VERSION "dbc-export 1 2026.26.6.5"

NS_ :

BS_:

BU_: APP APS BMS CC CMP CMPD CP DAS DI DIF DIR EPBL EPBR EVSE FC GTW HCML HCMR HVP ICR PCS PCS2 PLG PM PMF PMR PTC SCCM SCM SCS SDCR TAS UMC V2G VC VCBATT VCBATT0 VCBATT1 VCBATT2 VCFRONT VCFRONT1 VCFRONT2 VCLEFT VCRIGHT VCSEAT2L VCSEAT2R VCSEC

BO_ 968 EPBL_alertMatrix: 8 EPBL
 SG_ EPBL_matrixIndex M : 0|4@1+ (1,0) [0|15] "" Vector__XXX
 SG_ EPBL_a001_WatchdogReset m0 : 4|1@1+ (1,0) [0|1] "" Vector__XXX
 SG_ EPBL_a002_PowerLossReset m0 : 5|1@1+ (1,0) [0|1] "" Vector__XXX
 SG_ EPBL_a003_SWAssertion m0 : 6|1@1+ (1,0) [0|1] "" Vector__XXX
 SG_ EPBL_a005_CANTXError m0 : 8|1@1+ (1,0) [0|1] "" Vector__XXX
 SG_ EPBL_a006_CANTX_cyclicError m0 : 9|1@1+ (1,0) [0|1] "" Vector__XXX
 SG_ EPBL_a012_CPUReset m0 : 15|1@1+ (1,0) [0|1] "" Vector__XXX
 SG_ EPBL_a013_AlertManagerFault m0 : 16|1@1+ (1,0) [0|1] "" Vector__XXX
 SG_ EPBL_a015_NVMMError m0 : 18|1@1+ (1,0) [0|1] "" Vector__XXX
 SG_ EPBL_a016_NVMMRecordError m0 : 19|1@1+ (1,0) [0|1] "" Vector__XXX
 SG_ EPBL_a021_TaskSchedulerError m0 : 24|1@1+ (1,0) [0|1] "" Vector__XXX
 SG_ EPBL_a022_TaskInitError m0 : 25|1@1+ (1,0) [0|1] "" Vector__XXX
 SG_ EPBL_a029_CoreDump m0 : 32|1@1+ (1,0) [0|1] "" Vector__XXX
 SG_ EPBL_a030_ECULogUploadRequest m0 : 33|1@1+ (1,0) [0|1] "" Vector__XXX
 SG_ EPBL_a031_UDSActive m0 : 34|1@1+ (1,0) [0|1] "" Vector__XXX
 SG_ EPBL_a041_HighCPULoad m0 : 44|1@1+ (1,0) [0|1] "" Vector__XXX
 SG_ EPBL_a042_HighStackUsage m0 : 45|1@1+ (1,0) [0|1] "" Vector__XXX
 SG_ EPBL_a043_Task1msError m0 : 46|1@1+ (1,0) [0|1] "" Vector__XXX
 SG_ EPBL_a044_Task10msError m0 : 47|1@1+ (1,0) [0|1] "" Vector__XXX
 SG_ EPBL_a045_Task100msError m0 : 48|1@1+ (1,0) [0|1] "" Vector__XXX
 SG_ EPBL_a046_Task1000msError m0 : 49|1@1+ (1,0) [0|1] "" Vector__XXX
 SG_ EPBL_a057_HVP_MIA m0 : 60|1@1+ (1,0) [0|1] "" Vector__XXX
 SG_ EPBL_a058_inputRHighSyncDebug m0 : 61|1@1+ (1,0) [0|1] "" Vector__XXX
 SG_ EPBL_a059_inputResistanceHigh m0 : 62|1@1+ (1,0) [0|1] "" Vector__XXX
 SG_ EPBL_a060_engineeringBuild m0 : 63|1@1+ (1,0) [0|1] "" Vector__XXX
 SG_ EPBL_a061_XCPConnected m1 : 4|1@1+ (1,0) [0|1] "" Vector__XXX
 SG_ EPBL_a062_XCPWasConnected m1 : 5|1@1+ (1,0) [0|1] "" Vector__XXX
 SG_ EPBL_a063_SwitchFault m1 : 6|1@1+ (1,0) [0|1] "" Vector__XXX
 SG_ EPBL_a064_busSleepReqTimeout m1 : 7|1@1+ (1,0) [0|1] "" Vector__XXX
 SG_ EPBL_a081_APP_MIA m1 : 24|1@1+ (1,0) [0|1] "" Vector__XXX
 SG_ EPBL_a082_VCRIGHT_IPC_MIA m1 : 25|1@1+ (1,0) [0|1] "" Vector__XXX
 SG_ EPBL_a083_VCLEFT_IPC_MIA m1 : 26|1@1+ (1,0) [0|1] "" Vector__XXX
 SG_ EPBL_a084_TPMS_MIA m1 : 27|1@1+ (1,0) [0|1] "" Vector__XXX
 SG_ EPBL_a085_CCCM_MIA m1 : 28|1@1+ (1,0) [0|1] "" Vector__XXX
 SG_ EPBL_a086_VCBATT_MIA m1 : 29|1@1+ (1,0) [0|1] "" Vector__XXX
 SG_ EPBL_a087_DIREL_MIA m1 : 30|1@1+ (1,0) [0|1] "" Vector__XXX
 SG_ EPBL_a088_DIRER_MIA m1 : 31|1@1+ (1,0) [0|1] "" Vector__XXX
 SG_ EPBL_a089_IBST_MIA m1 : 32|1@1+ (1,0) [0|1] "" Vector__XXX
 SG_ EPBL_a090_APS_MIA m1 : 33|1@1+ (1,0) [0|1] "" Vector__XXX
 SG_ EPBL_a091_CMPD_MIA m1 : 34|1@1+ (1,0) [0|1] "" Vector__XXX
 SG_ EPBL_a092_VCSEATD_MIA m1 : 35|1@1+ (1,0) [0|1] "" Vector__XXX
 SG_ EPBL_a093_VCSEATP_MIA m1 : 36|1@1+ (1,0) [0|1] "" Vector__XXX
 SG_ EPBL_a094_EPAS3P_MIA m1 : 37|1@1+ (1,0) [0|1] "" Vector__XXX
 SG_ EPBL_a095_CHG_MIA m1 : 38|1@1+ (1,0) [0|1] "" Vector__XXX
 SG_ EPBL_a096_OCS1P_MIA m1 : 39|1@1+ (1,0) [0|1] "" Vector__XXX
 SG_ EPBL_a097_CMP_MIA m1 : 40|1@1+ (1,0) [0|1] "" Vector__XXX
 SG_ EPBL_a098_DIR_MIA m1 : 41|1@1+ (1,0) [0|1] "" Vector__XXX
 SG_ EPBL_a099_PARK_MIA m1 : 42|1@1+ (1,0) [0|1] "" Vector__XXX
 SG_ EPBL_a100_CANbus_MIA m1 : 43|1@1+ (1,0) [0|1] "" Vector__XXX
 SG_ EPBL_a101_PM_MIA m1 : 44|1@1+ (1,0) [0|1] "" Vector__XXX
 SG_ EPBL_a102_PTC_MIA m1 : 45|1@1+ (1,0) [0|1] "" Vector__XXX
 SG_ EPBL_a103_CP_MIA m1 : 46|1@1+ (1,0) [0|1] "" Vector__XXX
 SG_ EPBL_a104_DAS_MIA m1 : 47|1@1+ (1,0) [0|1] "" Vector__XXX
 SG_ EPBL_a105_TAS_MIA m1 : 48|1@1+ (1,0) [0|1] "" Vector__XXX
 SG_ EPBL_a106_PCS_MIA m1 : 49|1@1+ (1,0) [0|1] "" Vector__XXX
 SG_ EPBL_a107_BMS_MIA m1 : 50|1@1+ (1,0) [0|1] "" Vector__XXX
 SG_ EPBL_a108_DIF_MIA m1 : 51|1@1+ (1,0) [0|1] "" Vector__XXX
 SG_ EPBL_a109_RCM_MIA m1 : 52|1@1+ (1,0) [0|1] "" Vector__XXX
 SG_ EPBL_a110_GTW_MIA m1 : 53|1@1+ (1,0) [0|1] "" Vector__XXX
 SG_ EPBL_a111_EPBR_MIA m1 : 54|1@1+ (1,0) [0|1] "" Vector__XXX
 SG_ EPBL_a112_EPBL_MIA m1 : 55|1@1+ (1,0) [0|1] "" Vector__XXX
 SG_ EPBL_a113_UI_MIA m1 : 56|1@1+ (1,0) [0|1] "" Vector__XXX
 SG_ EPBL_a114_ESP_MIA m1 : 57|1@1+ (1,0) [0|1] "" Vector__XXX
 SG_ EPBL_a115_VCSEC_MIA m1 : 58|1@1+ (1,0) [0|1] "" Vector__XXX
 SG_ EPBL_a116_VCRIGHT_MIA m1 : 59|1@1+ (1,0) [0|1] "" Vector__XXX
 SG_ EPBL_a117_VCLEFT_MIA m1 : 60|1@1+ (1,0) [0|1] "" Vector__XXX
 SG_ EPBL_a118_VCFRONT_MIA m1 : 61|1@1+ (1,0) [0|1] "" Vector__XXX
 SG_ EPBL_a119_SCCM_MIA m1 : 62|1@1+ (1,0) [0|1] "" Vector__XXX
 SG_ EPBL_a120_DI_DRIVE_MIA m1 : 63|1@1+ (1,0) [0|1] "" Vector__XXX
 SG_ EPBL_a121_nDriveFault m2 : 4|1@1+ (1,0) [0|1] "" Vector__XXX
 SG_ EPBL_a122_Oc m2 : 5|1@1+ (1,0) [0|1] "" Vector__XXX
 SG_ EPBL_a123_Uc m2 : 6|1@1+ (1,0) [0|1] "" Vector__XXX
 SG_ EPBL_a124_calOutOfBounds m2 : 7|1@1+ (1,0) [0|1] "" Vector__XXX
 SG_ EPBL_a125_IdleVMismatch m2 : 8|1@1+ (1,0) [0|1] "" Vector__XXX
 SG_ EPBL_a126_MotorNVoltLow m2 : 9|1@1+ (1,0) [0|1] "" Vector__XXX
 SG_ EPBL_a127_MotorNVoltHigh m2 : 10|1@1+ (1,0) [0|1] "" Vector__XXX
 SG_ EPBL_a128_MotorPVoltHigh m2 : 11|1@1+ (1,0) [0|1] "" Vector__XXX
 SG_ EPBL_a129_ICR_MIA m2 : 12|1@1+ (1,0) [0|1] "" Vector__XXX
 SG_ EPBL_a130_BB_MIA m2 : 13|1@1+ (1,0) [0|1] "" Vector__XXX
 SG_ EPBL_a131_RCU_MIA m2 : 14|1@1+ (1,0) [0|1] "" Vector__XXX
 SG_ EPBL_a132_VCBATT1_MIA m2 : 15|1@1+ (1,0) [0|1] "" Vector__XXX
 SG_ EPBL_a133_VCBATT2_MIA m2 : 16|1@1+ (1,0) [0|1] "" Vector__XXX
 SG_ EPBL_a134_NvOv m2 : 17|1@1+ (1,0) [0|1] "" Vector__XXX
 SG_ EPBL_a135_NvUv m2 : 18|1@1+ (1,0) [0|1] "" Vector__XXX
 SG_ EPBL_a136_PvOv m2 : 19|1@1+ (1,0) [0|1] "" Vector__XXX
 SG_ EPBL_a137_PvUv m2 : 20|1@1+ (1,0) [0|1] "" Vector__XXX
 SG_ EPBL_a138_NvmDualFailure m2 : 21|1@1+ (1,0) [0|1] "" Vector__XXX
 SG_ EPBL_a139_NvmRedundancyLoss m2 : 22|1@1+ (1,0) [0|1] "" Vector__XXX
 SG_ EPBL_a140_NvmSlowWrite m2 : 23|1@1+ (1,0) [0|1] "" Vector__XXX
 SG_ EPBL_a141_invalidState m2 : 24|1@1+ (1,0) [0|1] "" Vector__XXX
 SG_ EPBL_a170_12vOv m2 : 53|1@1+ (1,0) [0|1] "" Vector__XXX
 SG_ EPBL_a171_12vUv m2 : 54|1@1+ (1,0) [0|1] "" Vector__XXX
 SG_ EPBL_a172_SPI_MIA m2 : 55|1@1+ (1,0) [0|1] "" Vector__XXX
 SG_ EPBL_a173_hiCurrentMissing m2 : 56|1@1+ (1,0) [0|1] "" Vector__XXX
 SG_ EPBL_a174_csmReleaseFailed m2 : 57|1@1+ (1,0) [0|1] "" Vector__XXX
 SG_ EPBL_a175_csmReleaseRetry m2 : 58|1@1+ (1,0) [0|1] "" Vector__XXX
 SG_ EPBL_a176_csmApplyFailed m2 : 59|1@1+ (1,0) [0|1] "" Vector__XXX
 SG_ EPBL_a177_csmApplyRetry m2 : 60|1@1+ (1,0) [0|1] "" Vector__XXX
 SG_ EPBL_a178_caliperStateUnknown m2 : 61|1@1+ (1,0) [0|1] "" Vector__XXX
 SG_ EPBL_a179_epbProblem m2 : 62|1@1+ (1,0) [0|1] "" Vector__XXX
 SG_ EPBL_a180_dynamicActive m2 : 63|1@1+ (1,0) [0|1] "" Vector__XXX
 SG_ EPBL_a181_TooSteepGradeToPark m3 : 4|1@1+ (1,0) [0|1] "" Vector__XXX
 SG_ EPBL_a182_OneEPBAppliedUnsecEnv m3 : 5|1@1+ (1,0) [0|1] "" Vector__XXX
 SG_ EPBL_a183_cdpNotAvailable m3 : 6|1@1+ (1,0) [0|1] "" Vector__XXX
 SG_ EPBL_a184_dynamicParkAbort m3 : 7|1@1+ (1,0) [0|1] "" Vector__XXX
 SG_ EPBL_a185_summonAborted m3 : 8|1@1+ (1,0) [0|1] "" Vector__XXX
 SG_ EPBL_a186_externalParkAbort m3 : 9|1@1+ (1,0) [0|1] "" Vector__XXX
 SG_ EPBL_a187_cdpDynamic m3 : 10|1@1+ (1,0) [0|1] "" Vector__XXX
 SG_ EPBL_a188_epbDynamic m3 : 11|1@1+ (1,0) [0|1] "" Vector__XXX
 SG_ EPBL_a189_epbDynamicParkCanceled m3 : 12|1@1+ (1,0) [0|1] "" Vector__XXX
 SG_ EPBL_a190_csmApplyDegraded m3 : 13|1@1+ (1,0) [0|1] "" Vector__XXX
 SG_ EPBL_a191_csmReleaseDegraded m3 : 14|1@1+ (1,0) [0|1] "" Vector__XXX
 SG_ EPBL_a195_parkForDriverIsLeaving m3 : 18|1@1+ (1,0) [0|1] "" Vector__XXX
 SG_ EPBL_a196_freeRollModeActive m3 : 19|1@1+ (1,0) [0|1] "" Vector__XXX
 SG_ EPBL_a197_freeRollModeAtSpeed m3 : 20|1@1+ (1,0) [0|1] "" Vector__XXX
 SG_ EPBL_a198_holdClampComplete m3 : 21|1@1+ (1,0) [0|1] "" Vector__XXX
 SG_ EPBL_a200_PmUnparkNotAllowed m3 : 23|1@1+ (1,0) [0|1] "" Vector__XXX
 SG_ EPBL_a202_remoteEpbConfigIncompa m3 : 25|1@1+ (1,0) [0|1] "" Vector__XXX
 SG_ EPBL_a203_hwBrakeTypeMismatch m3 : 26|1@1+ (1,0) [0|1] "" Vector__XXX
 SG_ EPBL_a210_parkForDriverIsLeaving m3 : 33|1@1+ (1,0) [0|1] "" Vector__XXX
 SG_ EPBL_a216_SPI_MIA_debugData1 m3 : 39|1@1+ (1,0) [0|1] "" Vector__XXX
 SG_ EPBL_a217_SPI_MIA_debugData2 m3 : 40|1@1+ (1,0) [0|1] "" Vector__XXX
 SG_ EPBL_a225_epbActiveDecel m3 : 48|1@1+ (1,0) [0|1] "" Vector__XXX
 SG_ EPBL_a241_diOutputLocked m4 : 4|1@1+ (1,0) [0|1] "" Vector__XXX
 SG_ EPBL_a242_hvOutputLocked m4 : 5|1@1+ (1,0) [0|1] "" Vector__XXX
 SG_ EPBL_a243_bdwUnavailable m4 : 6|1@1+ (1,0) [0|1] "" Vector__XXX
 SG_ EPBL_a244_WinchModeActive m4 : 7|1@1+ (1,0) [0|1] "" Vector__XXX
 SG_ EPBL_a245_serviceModeActive m4 : 8|1@1+ (1,0) [0|1] "" Vector__XXX
 SG_ EPBL_a246_idleFaultApply m4 : 9|1@1+ (1,0) [0|1] "" Vector__XXX
 SG_ EPBL_a247_csmDynamicApplyRetry m4 : 10|1@1+ (1,0) [0|1] "" Vector__XXX
 SG_ EPBL_a248_csmDynamicApplyFailed m4 : 11|1@1+ (1,0) [0|1] "" Vector__XXX
 SG_ EPBL_a249_idleFaultRelease m4 : 12|1@1+ (1,0) [0|1] "" Vector__XXX
 SG_ EPBL_a250_WinchModeCanceled m4 : 13|1@1+ (1,0) [0|1] "" Vector__XXX
 SG_ EPBL_a251_currentVarianceHigh m4 : 14|1@1+ (1,0) [0|1] "" Vector__XXX
 SG_ EPBL_a252_winchModePending m4 : 15|1@1+ (1,0) [0|1] "" Vector__XXX
 SG_ EPBL_a253_esmReleaseBlocked m4 : 16|1@1+ (1,0) [0|1] "" Vector__XXX
 SG_ EPBL_a254_showStalkParkButtonFau m4 : 17|1@1+ (1,0) [0|1] "" Vector__XXX
 SG_ EPBL_a256_epbSystemApply m4 : 19|1@1+ (1,0) [0|1] "" Vector__XXX
 SG_ EPBL_a261_winchModeWithoutSteeri m4 : 24|1@1+ (1,0) [0|1] "" Vector__XXX
 SG_ EPBL_a262_cannotPrepareWinchMode m4 : 25|1@1+ (1,0) [0|1] "" Vector__XXX
 SG_ EPBL_a263_epbRecoveryPark m4 : 26|1@1+ (1,0) [0|1] "" Vector__XXX
 SG_ EPBL_a264_winchModeDeactivated m4 : 27|1@1+ (1,0) [0|1] "" Vector__XXX
 SG_ EPBL_a272_vhclPwrStateMsmtch m4 : 35|1@1+ (1,0) [0|1] "" Vector__XXX
 SG_ EPBL_a300_leftRightConfusion m4 : 63|1@1+ (1,0) [0|1] "" Vector__XXX
 SG_ EPBL_a301_oocSpeedViolation m5 : 4|1@1+ (1,0) [0|1] "" Vector__XXX
 SG_ EPBL_a302_csmLongRelease m5 : 5|1@1+ (1,0) [0|1] "" Vector__XXX
 SG_ EPBL_a303_clampingOccuredEarly m5 : 6|1@1+ (1,0) [0|1] "" Vector__XXX
 SG_ EPBL_a304_rearSeatControllerEFus m5 : 7|1@1+ (1,0) [0|1] "" Vector__XXX
 SG_ EPBL_a305_premiumAmpEFuseTrip m5 : 8|1@1+ (1,0) [0|1] "" Vector__XXX
 SG_ EPBL_a330_parkForApIsLeaving m5 : 33|1@1+ (1,0) [0|1] "" Vector__XXX
 SG_ EPBL_a350_ensOutOfRange m5 : 53|1@1+ (1,0) [0|1] "" Vector__XXX
 SG_ EPBL_a352_audioCurrentSpikeData m5 : 55|1@1+ (1,0) [0|1] "" Vector__XXX
 SG_ EPBL_a353_missingSpeedUnableToPa m5 : 56|1@1+ (1,0) [0|1] "" Vector__XXX
 SG_ EPBL_a354_parkedForLowBrakeFluid m5 : 57|1@1+ (1,0) [0|1] "" Vector__XXX
 SG_ EPBL_a355_brakeHwAndEpbHwMismatc m5 : 58|1@1+ (1,0) [0|1] "" Vector__XXX
 SG_ EPBL_a356_parkingForStationaryDe m5 : 59|1@1+ (1,0) [0|1] "" Vector__XXX
 SG_ EPBL_a357_brakesTooHotForSlope m5 : 60|1@1+ (1,0) [0|1] "" Vector__XXX
 SG_ EPBL_a358_brakesTooHotForSlopeWi m5 : 61|1@1+ (1,0) [0|1] "" Vector__XXX
 SG_ EPBL_a360_ibstBrakeSwitchInvalid m5 : 63|1@1+ (1,0) [0|1] "" Vector__XXX
 SG_ EPBL_a361_espBrakeSwitchInvalid m6 : 4|1@1+ (1,0) [0|1] "" Vector__XXX
 SG_ EPBL_a362_ibstPressedEspNotPress m6 : 5|1@1+ (1,0) [0|1] "" Vector__XXX
 SG_ EPBL_a363_ibstNotPressedEspPress m6 : 6|1@1+ (1,0) [0|1] "" Vector__XXX
 SG_ EPBL_a364_espMasterCylCompOverTh m6 : 7|1@1+ (1,0) [0|1] "" Vector__XXX
 SG_ EPBL_a365_TooSteepToParkWithTrai m6 : 8|1@1+ (1,0) [0|1] "" Vector__XXX
 SG_ EPBL_a366_TooSteepToParkWithTrai m6 : 9|1@1+ (1,0) [0|1] "" Vector__XXX
 SG_ EPBL_a370_imposterDetected m6 : 13|1@1+ (1,0) [0|1] "" Vector__XXX
 SG_ EPBL_a380_canError m6 : 23|1@1+ (1,0) [0|1] "" Vector__XXX
 SG_ EPBL_a381_LIPC_canFault m6 : 24|1@1+ (1,0) [0|1] "" Vector__XXX
 SG_ EPBL_a382_CH_canFault m6 : 25|1@1+ (1,0) [0|1] "" Vector__XXX

BO_ 1992 EPBL_info: 8 EPBL
 SG_ EPBL_infoIndex M : 0|8@1+ (1,0) [0|255] "" Vector__XXX
 SG_ EPBL_infoBuildType m10 : 8|3@1+ (1,0) [0|7] "" Vector__XXX
 SG_ EPBL_infoBuildConfigId m10 : 16|16@1+ (1,0) [0|65535] "" Vector__XXX
 SG_ EPBL_infoHardwareId m10 : 32|16@1+ (1,0) [0|65535] "" Vector__XXX
 SG_ EPBL_infoComponentId m10 : 48|16@1+ (1,0) [0|65535] "" Vector__XXX
 SG_ EPBL_infoPcbaId m11 : 8|8@1+ (1,0) [0|255] "" Vector__XXX
 SG_ EPBL_infoAssemblyId m11 : 16|8@1+ (1,0) [0|254] "" Vector__XXX
 SG_ EPBL_infoUsageId m11 : 24|16@1+ (1,0) [0|65535] "" Vector__XXX
 SG_ EPBL_infoSubUsageId m11 : 40|16@1+ (1,0) [0|65535] "" Vector__XXX
 SG_ EPBL_infoAppCrc m13 : 8|32@1+ (1,0) [0|4294967295] "" Vector__XXX
 SG_ EPBL_infoAppGitHash m17 : 8|56@1+ (1,0) [0|7.20575940379e+16] "" Vector__XXX
 SG_ EPBL_infoBootGitHash m18 : 8|56@1+ (1,0) [0|7.20575940379e+16] "" Vector__XXX
 SG_ EPBL_infoPlatformType m19 : 8|8@1+ (1,0) [0|255] "" Vector__XXX
 SG_ EPBL_infoBootUdsProtoVersion m20 : 8|16@1+ (1,0) [0|65535] "" Vector__XXX
 SG_ EPBL_infoBootCrc m20 : 24|32@1+ (1,0) [0|4294967295] "" Vector__XXX

BO_ 648 EPBL_internalStatus: 8 EPBL
 SG_ EPBL_unitStatus : 0|5@1+ (1,0) [0|31] "" Vector__XXX
 SG_ EPBL_unitFaultStatus : 5|2@1+ (1,0) [0|3] "" Vector__XXX
 SG_ EPBL_summonState : 8|3@1+ (1,0) [0|7] "" Vector__XXX
 SG_ EPBL_disconnected : 11|1@1+ (1,0) [0|1] "" Vector__XXX
 SG_ EPBL_pistonTouchingRotor : 12|1@1+ (1,0) [0|1] "" Vector__XXX
 SG_ EPBL_csmFaultReason : 13|5@1+ (1,0) [0|31] "" Vector__XXX
 SG_ EPBL_esmOperationTrigger : 18|6@1+ (1,0) [0|63] "" Vector__XXX
 SG_ EPBL_summonFaultReason : 24|5@1+ (1,0) [0|31] "" Vector__XXX
 SG_ EPBL_localServiceModeActive : 29|1@1+ (1,0) [0|1] "" Vector__XXX
 SG_ EPBL_localCdpState : 30|2@1+ (1,0) [0|3] "" Vector__XXX
 SG_ EPBL_chimeRequestLocal : 33|3@1+ (1,0) [0|7] "" Vector__XXX
 SG_ EPBL_telltaleLocal : 39|3@1+ (1,0) [0|6] "" Vector__XXX
 SG_ EPBL_driverIsLeavingLocal : 42|1@1+ (1,0) [0|1] "" Vector__XXX
 SG_ EPBL_driverIsLeavingAnySpeedLoca : 43|1@1+ (1,0) [0|1] "" Vector__XXX
 SG_ EPBL_internalCDPRequest : 44|1@1+ (1,0) [0|1] "" Vector__XXX
 SG_ EPBL_esmSpeedClass : 45|3@1+ (1,0) [0|7] "" Vector__XXX
 SG_ EPBL_learnedEpbConfig : 48|4@1+ (1,0) [0|15] "" Vector__XXX
 SG_ EPBL_internalStatusCounter : 52|4@1+ (1,0) [0|15] "" Vector__XXX
 SG_ EPBL_internalStatusChecksum : 56|8@1+ (1,0) [0|255] "" Vector__XXX

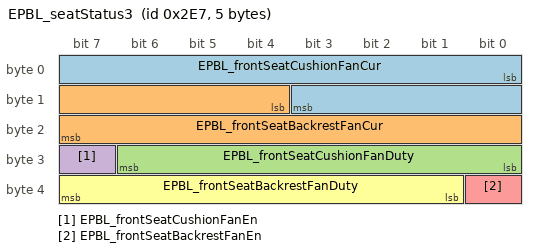
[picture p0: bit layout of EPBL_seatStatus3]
BO_ 743 EPBL_seatStatus3: 5 EPBL
 SG_ EPBL_frontSeatCushionFanCur : 0|12@1+ (0.01,0) [0|40.95] "A" Vector__XXX
 SG_ EPBL_frontSeatBackrestFanCur : 12|12@1+ (0.01,0) [0|40.95] "A" Vector__XXX
 SG_ EPBL_frontSeatCushionFanDuty : 24|7@1+ (1,0) [0|100] "%" Vector__XXX
 SG_ EPBL_frontSeatCushionFanEn : 31|1@1+ (1,0) [0|1] "" Vector__XXX
 SG_ EPBL_frontSeatBackrestFanEn : 32|1@1+ (1,0) [0|1] "" Vector__XXX
 SG_ EPBL_frontSeatBackrestFanDuty : 33|7@1+ (1,0) [0|100] "%" Vector__XXX

BO_ 680 EPBL_status: 8 EPBL
 SG_ EPBL_systemStatus : 0|4@1+ (1,0) [0|15] "" Vector__XXX
 SG_ EPBL_freeRollModeStatus : 4|2@1+ (1,0) [0|3] "" Vector__XXX
 SG_ EPBL_driverIsLeaving : 6|1@1+ (1,0) [0|1] "" Vector__XXX
 SG_ EPBL_driverIsLeavingAnySpeed : 7|1@1+ (1,0) [0|1] "" Vector__XXX
 SG_ EPBL_systemCdpAvailable : 8|1@1+ (1,0) [0|1] "" Vector__XXX
 SG_ EPBL_chimeRequest : 9|3@1+ (1,0) [0|7] "" Vector__XXX
 SG_ EPBL_telltale : 12|3@1+ (1,0) [0|6] "" Vector__XXX
 SG_ EPBL_contactorCycleNotNeededForW : 15|1@1+ (1,0) [0|1] "" Vector__XXX
 SG_ EPBL_redundantBrakingEnabled : 16|1@1+ (1,0) [0|1] "" Vector__XXX
 SG_ EPBL_summonEnabled : 17|1@1+ (1,0) [0|1] "" Vector__XXX
 SG_ EPBL_brakeLight : 18|1@1+ (1,0) [0|1] "" Vector__XXX
 SG_ EPBL_epbConfigMismatch : 19|1@1+ (1,0) [0|1] "" Vector__XXX
 SG_ EPBL_brakeConfirmedPressed : 20|1@1+ (1,0) [0|1] "" Vector__XXX
 SG_ EPBL_requestUserConfirmation : 21|1@1+ (1,0) [0|1] "" Vector__XXX
 SG_ EPBL_uiWinchModeMiscBlocking : 22|1@1+ (1,0) [0|1] "" Vector__XXX
 SG_ EPBL_winchModeActive : 23|1@1+ (1,0) [0|1] "" Vector__XXX
 SG_ EPBL_updateMode : 24|1@1+ (1,0) [0|1] "" Vector__XXX
 SG_ EPBL_winchModePermissive : 25|1@1+ (1,0) [0|1] "" Vector__XXX
 SG_ EPBL_winchModePending : 26|1@1+ (1,0) [0|1] "" Vector__XXX
 SG_ EPBL_cdpRequest : 27|1@1+ (1,0) [0|1] "" Vector__XXX
 SG_ EPBL_uiParkAvailable : 28|2@1+ (1,0) [0|3] "" Vector__XXX
 SG_ EPBL_brakeDiscWipeRequest : 30|2@1+ (1,0) [0|2] "" Vector__XXX
 SG_ EPBL_showUiGearShifter : 32|1@1+ (1,0) [0|1] "" Vector__XXX
 SG_ EPBL_uiWinchModeLvStatus : 33|2@1+ (1,0) [0|3] "" Vector__XXX
 SG_ EPBL_autonomyBehavior : 43|2@1+ (1,0) [0|3] "" Vector__XXX
 SG_ EPBL_showStalkFaultedOnUi : 45|1@1+ (1,0) [0|1] "" Vector__XXX
 SG_ EPBL_espPowerRequest : 46|1@1+ (1,0) [0|1] "" Vector__XXX
 SG_ EPBL_okToPark : 47|1@1+ (1,0) [0|1] "" Vector__XXX
 SG_ EPBL_hornRequest : 48|1@1+ (1,0) [0|1] "" Vector__XXX
 SG_ EPBL_winchModeAvailable : 49|1@1+ (1,0) [0|1] "" Vector__XXX
 SG_ EPBL_bothDisconnected : 50|1@1+ (1,0) [0|1] "" Vector__XXX
 SG_ EPBL_blockDrive : 51|1@1+ (1,0) [0|1] "" Vector__XXX
 SG_ EPBL_statusCounter : 52|4@1+ (1,0) [0|15] "" Vector__XXX
 SG_ EPBL_statusChecksum : 56|8@1+ (1,0) [0|255] "" Vector__XXX

BO_ 1573 EPBL_udsResponse: 8 EPBL
 SG_ EPBL_udsResponseData_H : 7|32@0+ (1,0) [0|4294967295] "" Vector__XXX
 SG_ EPBL_udsResponseData_L : 39|32@0+ (1,0) [0|4294967295] "" Vector__XXX

BO_TX_BU_ 968 : EPBL;
BO_TX_BU_ 1992 : EPBL;
BO_TX_BU_ 648 : EPBL;
BO_TX_BU_ 743 : EPBL;
BO_TX_BU_ 680 : EPBL;
BO_TX_BU_ 1573 : EPBL;
CM_ BO_ 968 "Left electric parking brake message: alert matrix; frame length observed on a vehicle bus";
CM_ SG_ 968 EPBL_matrixIndex "Left electric parking brake: matrix index";
CM_ SG_ 968 EPBL_a001_WatchdogReset "Left electric parking brake: a001 watchdog reset";
CM_ SG_ 968 EPBL_a002_PowerLossReset "Left electric parking brake: a002 power loss reset";
CM_ SG_ 968 EPBL_a003_SWAssertion "Left electric parking brake: a003 SW assertion";
CM_ SG_ 968 EPBL_a005_CANTXError "Left electric parking brake: a005 CANTX error";
CM_ SG_ 968 EPBL_a006_CANTX_cyclicError "Left electric parking brake: a006 CANTX cyclic error";
CM_ SG_ 968 EPBL_a012_CPUReset "Left electric parking brake: a012 CPU reset";
CM_ SG_ 968 EPBL_a013_AlertManagerFault "Left electric parking brake: a013 alert manager fault";
CM_ SG_ 968 EPBL_a015_NVMMError "Left electric parking brake: a015 NVMM error";
CM_ SG_ 968 EPBL_a016_NVMMRecordError "Left electric parking brake: a016 NVMM record error";
CM_ SG_ 968 EPBL_a021_TaskSchedulerError "Left electric parking brake: a021 task scheduler error";
CM_ SG_ 968 EPBL_a022_TaskInitError "Left electric parking brake: a022 task init error";
CM_ SG_ 968 EPBL_a029_CoreDump "Left electric parking brake: a029 core dump";
CM_ SG_ 968 EPBL_a030_ECULogUploadRequest "Left electric parking brake: a030 ECU log upload request";
CM_ SG_ 968 EPBL_a031_UDSActive "Left electric parking brake: a031 UDS active";
CM_ SG_ 968 EPBL_a041_HighCPULoad "Left electric parking brake: a041 high CPU load";
CM_ SG_ 968 EPBL_a042_HighStackUsage "Left electric parking brake: a042 high stack usage";
CM_ SG_ 968 EPBL_a043_Task1msError "Left electric parking brake: a043 task1ms error";
CM_ SG_ 968 EPBL_a044_Task10msError "Left electric parking brake: a044 task10ms error";
CM_ SG_ 968 EPBL_a045_Task100msError "Left electric parking brake: a045 task100ms error";
CM_ SG_ 968 EPBL_a046_Task1000msError "Left electric parking brake: a046 task1000ms error";
CM_ SG_ 968 EPBL_a057_HVP_MIA "Left electric parking brake: a057 HVP MIA";
CM_ SG_ 968 EPBL_a058_inputRHighSyncDebug "Left electric parking brake: a058 input r high sync debug";
CM_ SG_ 968 EPBL_a059_inputResistanceHigh "Left electric parking brake: a059 input resistance high";
CM_ SG_ 968 EPBL_a060_engineeringBuild "Left electric parking brake: a060 engineering build";
CM_ SG_ 968 EPBL_a061_XCPConnected "Left electric parking brake: a061 XCP connected";
CM_ SG_ 968 EPBL_a062_XCPWasConnected "Left electric parking brake: a062 XCP was connected";
CM_ SG_ 968 EPBL_a063_SwitchFault "Left electric parking brake: a063 switch fault";
CM_ SG_ 968 EPBL_a064_busSleepReqTimeout "Left electric parking brake: a064 bus sleep req timeout";
CM_ SG_ 968 EPBL_a081_APP_MIA "Left electric parking brake: a081 APP MIA";
CM_ SG_ 968 EPBL_a082_VCRIGHT_IPC_MIA "Left electric parking brake: a082 VCRIGHT IPC MIA";
CM_ SG_ 968 EPBL_a083_VCLEFT_IPC_MIA "Left electric parking brake: a083 VCLEFT IPC MIA";
CM_ SG_ 968 EPBL_a084_TPMS_MIA "Left electric parking brake: a084 TPMS MIA";
CM_ SG_ 968 EPBL_a085_CCCM_MIA "Left electric parking brake: a085 CCCM MIA";
CM_ SG_ 968 EPBL_a086_VCBATT_MIA "Left electric parking brake: a086 VCBATT MIA";
CM_ SG_ 968 EPBL_a087_DIREL_MIA "Left electric parking brake: a087 DIREL MIA";
CM_ SG_ 968 EPBL_a088_DIRER_MIA "Left electric parking brake: a088 DIRER MIA";
CM_ SG_ 968 EPBL_a089_IBST_MIA "Left electric parking brake: a089 IBST MIA";
CM_ SG_ 968 EPBL_a090_APS_MIA "Left electric parking brake: a090 APS MIA";
CM_ SG_ 968 EPBL_a091_CMPD_MIA "Left electric parking brake: a091 CMPD MIA";
CM_ SG_ 968 EPBL_a092_VCSEATD_MIA "Left electric parking brake: a092 VCSEATD MIA";
CM_ SG_ 968 EPBL_a093_VCSEATP_MIA "Left electric parking brake: a093 VCSEATP MIA";
CM_ SG_ 968 EPBL_a094_EPAS3P_MIA "Left electric parking brake: a094 EPAS3 p MIA";
CM_ SG_ 968 EPBL_a095_CHG_MIA "Left electric parking brake: a095 CHG MIA";
CM_ SG_ 968 EPBL_a096_OCS1P_MIA "Left electric parking brake: a096 OCS1 p MIA";
CM_ SG_ 968 EPBL_a097_CMP_MIA "Left electric parking brake: a097 CMP MIA";
CM_ SG_ 968 EPBL_a098_DIR_MIA "Left electric parking brake: a098 DIR MIA";
CM_ SG_ 968 EPBL_a099_PARK_MIA "Left electric parking brake: a099 PARK MIA";
CM_ SG_ 968 EPBL_a100_CANbus_MIA "Left electric parking brake: a100 CA nbus MIA";
CM_ SG_ 968 EPBL_a101_PM_MIA "Left electric parking brake: a101 PM MIA";
CM_ SG_ 968 EPBL_a102_PTC_MIA "Left electric parking brake: a102 PTC MIA";
CM_ SG_ 968 EPBL_a103_CP_MIA "Left electric parking brake: a103 CP MIA";
CM_ SG_ 968 EPBL_a104_DAS_MIA "Left electric parking brake: a104 DAS MIA";
CM_ SG_ 968 EPBL_a105_TAS_MIA "Left electric parking brake: a105 TAS MIA";
CM_ SG_ 968 EPBL_a106_PCS_MIA "Left electric parking brake: a106 PCS MIA";
CM_ SG_ 968 EPBL_a107_BMS_MIA "Left electric parking brake: a107 BMS MIA";
CM_ SG_ 968 EPBL_a108_DIF_MIA "Left electric parking brake: a108 DIF MIA";
CM_ SG_ 968 EPBL_a109_RCM_MIA "Left electric parking brake: a109 RCM MIA";
CM_ SG_ 968 EPBL_a110_GTW_MIA "Left electric parking brake: a110 GTW MIA";
CM_ SG_ 968 EPBL_a111_EPBR_MIA "Left electric parking brake: a111 EPBR MIA";
CM_ SG_ 968 EPBL_a112_EPBL_MIA "Left electric parking brake: a112 EPBL MIA";
CM_ SG_ 968 EPBL_a113_UI_MIA "Left electric parking brake: a113 UI MIA";
CM_ SG_ 968 EPBL_a114_ESP_MIA "Left electric parking brake: a114 ESP MIA";
CM_ SG_ 968 EPBL_a115_VCSEC_MIA "Left electric parking brake: a115 VCSEC MIA";
CM_ SG_ 968 EPBL_a116_VCRIGHT_MIA "Left electric parking brake: a116 VCRIGHT MIA";
CM_ SG_ 968 EPBL_a117_VCLEFT_MIA "Left electric parking brake: a117 VCLEFT MIA";
CM_ SG_ 968 EPBL_a118_VCFRONT_MIA "Left electric parking brake: a118 VCFRONT MIA";
CM_ SG_ 968 EPBL_a119_SCCM_MIA "Left electric parking brake: a119 SCCM MIA";
CM_ SG_ 968 EPBL_a120_DI_DRIVE_MIA "Left electric parking brake: a120 DI DRIVE MIA";
CM_ SG_ 968 EPBL_a121_nDriveFault "Left electric parking brake: a121 n drive fault";
CM_ SG_ 968 EPBL_a122_Oc "Left electric parking brake: a122 oc";
CM_ SG_ 968 EPBL_a123_Uc "Left electric parking brake: a123 uc";
CM_ SG_ 968 EPBL_a124_calOutOfBounds "Left electric parking brake: a124 cal out of bounds";
CM_ SG_ 968 EPBL_a125_IdleVMismatch "Left electric parking brake: a125 idle v mismatch";
CM_ SG_ 968 EPBL_a126_MotorNVoltLow "Left electric parking brake: a126 motor n volt low";
CM_ SG_ 968 EPBL_a127_MotorNVoltHigh "Left electric parking brake: a127 motor n volt high";
CM_ SG_ 968 EPBL_a128_MotorPVoltHigh "Left electric parking brake: a128 motor p volt high";
CM_ SG_ 968 EPBL_a129_ICR_MIA "Left electric parking brake: a129 ICR MIA";
CM_ SG_ 968 EPBL_a130_BB_MIA "Left electric parking brake: a130 BB MIA";
CM_ SG_ 968 EPBL_a131_RCU_MIA "Left electric parking brake: a131 RCU MIA";
CM_ SG_ 968 EPBL_a132_VCBATT1_MIA "Left electric parking brake: a132 VCBATT1 MIA";
CM_ SG_ 968 EPBL_a133_VCBATT2_MIA "Left electric parking brake: a133 VCBATT2 MIA";
CM_ SG_ 968 EPBL_a134_NvOv "Left electric parking brake: a134 nv ov";
CM_ SG_ 968 EPBL_a135_NvUv "Left electric parking brake: a135 nv uv";
CM_ SG_ 968 EPBL_a136_PvOv "Left electric parking brake: a136 pv ov";
CM_ SG_ 968 EPBL_a137_PvUv "Left electric parking brake: a137 pv uv";
CM_ SG_ 968 EPBL_a138_NvmDualFailure "Left electric parking brake: a138 nvm dual failure";
CM_ SG_ 968 EPBL_a139_NvmRedundancyLoss "Left electric parking brake: a139 nvm redundancy loss";
CM_ SG_ 968 EPBL_a140_NvmSlowWrite "Left electric parking brake: a140 nvm slow write";
CM_ SG_ 968 EPBL_a141_invalidState "Left electric parking brake: a141 invalid state";
CM_ SG_ 968 EPBL_a170_12vOv "Left electric parking brake: a170 12v ov";
CM_ SG_ 968 EPBL_a171_12vUv "Left electric parking brake: a171 12v uv";
CM_ SG_ 968 EPBL_a172_SPI_MIA "Left electric parking brake: a172 SPI MIA";
CM_ SG_ 968 EPBL_a173_hiCurrentMissing "Left electric parking brake: a173 hi current missing";
CM_ SG_ 968 EPBL_a174_csmReleaseFailed "Left electric parking brake: a174 csm release failed";
CM_ SG_ 968 EPBL_a175_csmReleaseRetry "Left electric parking brake: a175 csm release retry";
CM_ SG_ 968 EPBL_a176_csmApplyFailed "Left electric parking brake: a176 csm apply failed";
CM_ SG_ 968 EPBL_a177_csmApplyRetry "Left electric parking brake: a177 csm apply retry";
CM_ SG_ 968 EPBL_a178_caliperStateUnknown "Left electric parking brake: a178 caliper state unknown";
CM_ SG_ 968 EPBL_a179_epbProblem "Left electric parking brake: a179 epb problem";
CM_ SG_ 968 EPBL_a180_dynamicActive "Left electric parking brake: a180 dynamic active";
CM_ SG_ 968 EPBL_a181_TooSteepGradeToPark "Left electric parking brake: a181 too steep grade to park";
CM_ SG_ 968 EPBL_a182_OneEPBAppliedUnsecEnv "Left electric parking brake: a182 one EPB applied unsec env";
CM_ SG_ 968 EPBL_a183_cdpNotAvailable "Left electric parking brake: a183 cdp not available";
CM_ SG_ 968 EPBL_a184_dynamicParkAbort "Left electric parking brake: a184 dynamic park abort";
CM_ SG_ 968 EPBL_a185_summonAborted "Left electric parking brake: a185 summon aborted";
CM_ SG_ 968 EPBL_a186_externalParkAbort "Left electric parking brake: a186 external park abort";
CM_ SG_ 968 EPBL_a187_cdpDynamic "Left electric parking brake: a187 cdp dynamic";
CM_ SG_ 968 EPBL_a188_epbDynamic "Left electric parking brake: a188 epb dynamic";
CM_ SG_ 968 EPBL_a189_epbDynamicParkCanceled "Left electric parking brake: a189 epb dynamic park canceled";
CM_ SG_ 968 EPBL_a190_csmApplyDegraded "Left electric parking brake: a190 csm apply degraded";
CM_ SG_ 968 EPBL_a191_csmReleaseDegraded "Left electric parking brake: a191 csm release degraded";
CM_ SG_ 968 EPBL_a195_parkForDriverIsLeaving "Left electric parking brake: a195 park for driver is leaving";
CM_ SG_ 968 EPBL_a196_freeRollModeActive "Left electric parking brake: a196 free roll mode active";
CM_ SG_ 968 EPBL_a197_freeRollModeAtSpeed "Left electric parking brake: a197 free roll mode at speed";
CM_ SG_ 968 EPBL_a198_holdClampComplete "Left electric parking brake: a198 hold clamp complete";
CM_ SG_ 968 EPBL_a200_PmUnparkNotAllowed "Left electric parking brake: a200 pm unpark not allowed";
CM_ SG_ 968 EPBL_a202_remoteEpbConfigIncompa "Left electric parking brake: a202 remote epb config incompatible";
CM_ SG_ 968 EPBL_a203_hwBrakeTypeMismatch "Left electric parking brake: a203 hw brake type mismatch";
CM_ SG_ 968 EPBL_a210_parkForDriverIsLeaving "Left electric parking brake: a210 park for driver is leaving debug";
CM_ SG_ 968 EPBL_a216_SPI_MIA_debugData1 "Left electric parking brake: a216 SPI MIA debug data1";
CM_ SG_ 968 EPBL_a217_SPI_MIA_debugData2 "Left electric parking brake: a217 SPI MIA debug data2";
CM_ SG_ 968 EPBL_a225_epbActiveDecel "Left electric parking brake: a225 epb active decel";
CM_ SG_ 968 EPBL_a241_diOutputLocked "Left electric parking brake: a241 di output locked";
CM_ SG_ 968 EPBL_a242_hvOutputLocked "Left electric parking brake: a242 hv output locked";
CM_ SG_ 968 EPBL_a243_bdwUnavailable "Left electric parking brake: a243 bdw unavailable";
CM_ SG_ 968 EPBL_a244_WinchModeActive "Left electric parking brake: a244 winch mode active";
CM_ SG_ 968 EPBL_a245_serviceModeActive "Signal reported by Left electric parking brake";
CM_ SG_ 968 EPBL_a246_idleFaultApply "Left electric parking brake: a246 idle fault apply";
CM_ SG_ 968 EPBL_a247_csmDynamicApplyRetry "Left electric parking brake: a247 csm dynamic apply retry";
CM_ SG_ 968 EPBL_a248_csmDynamicApplyFailed "Left electric parking brake: a248 csm dynamic apply failed";
CM_ SG_ 968 EPBL_a249_idleFaultRelease "Left electric parking brake: a249 idle fault release";
CM_ SG_ 968 EPBL_a250_WinchModeCanceled "Left electric parking brake: a250 winch mode canceled";
CM_ SG_ 968 EPBL_a251_currentVarianceHigh "Left electric parking brake: a251 current variance high";
CM_ SG_ 968 EPBL_a252_winchModePending "Left electric parking brake: a252 winch mode pending";
CM_ SG_ 968 EPBL_a253_esmReleaseBlocked "Left electric parking brake: a253 esm release blocked";
CM_ SG_ 968 EPBL_a254_showStalkParkButtonFau "Left electric parking brake: a254 show stalk park button fault on ui";
CM_ SG_ 968 EPBL_a256_epbSystemApply "Left electric parking brake: a256 epb system apply";
CM_ SG_ 968 EPBL_a261_winchModeWithoutSteeri "Left electric parking brake: a261 winch mode without steering";
CM_ SG_ 968 EPBL_a262_cannotPrepareWinchMode "Left electric parking brake: a262 cannot prepare winch mode";
CM_ SG_ 968 EPBL_a263_epbRecoveryPark "Left electric parking brake: a263 epb recovery park";
CM_ SG_ 968 EPBL_a264_winchModeDeactivated "Left electric parking brake: a264 winch mode deactivated";
CM_ SG_ 968 EPBL_a272_vhclPwrStateMsmtch "Left electric parking brake: a272 vhcl pwr state msmtch";
CM_ SG_ 968 EPBL_a300_leftRightConfusion "Left electric parking brake: a300 left right confusion";
CM_ SG_ 968 EPBL_a301_oocSpeedViolation "Left electric parking brake: a301 ooc speed violation";
CM_ SG_ 968 EPBL_a302_csmLongRelease "Left electric parking brake: a302 csm long release";
CM_ SG_ 968 EPBL_a303_clampingOccuredEarly "Left electric parking brake: a303 clamping occured early";
CM_ SG_ 968 EPBL_a304_rearSeatControllerEFus "Left electric parking brake: a304 rear seat controller e fuse trip";
CM_ SG_ 968 EPBL_a305_premiumAmpEFuseTrip "Left electric parking brake: a305 premium amp e fuse trip";
CM_ SG_ 968 EPBL_a330_parkForApIsLeaving "Left electric parking brake: a330 park for ap is leaving";
CM_ SG_ 968 EPBL_a350_ensOutOfRange "Left electric parking brake: a350 ens out of range";
CM_ SG_ 968 EPBL_a352_audioCurrentSpikeData "Left electric parking brake: a352 audio current spike data";
CM_ SG_ 968 EPBL_a353_missingSpeedUnableToPa "Left electric parking brake: a353 missing speed unable to park";
CM_ SG_ 968 EPBL_a354_parkedForLowBrakeFluid "Left electric parking brake: a354 parked for low brake fluid mode";
CM_ SG_ 968 EPBL_a355_brakeHwAndEpbHwMismatc "Left electric parking brake: a355 brake hw and epb hw mismatch";
CM_ SG_ 968 EPBL_a356_parkingForStationaryDe "Left electric parking brake: a356 parking for stationary detect";
CM_ SG_ 968 EPBL_a357_brakesTooHotForSlope "Left electric parking brake: a357 brakes too hot for slope";
CM_ SG_ 968 EPBL_a358_brakesTooHotForSlopeWi "Left electric parking brake: a358 brakes too hot for slope with only one epb";
CM_ SG_ 968 EPBL_a360_ibstBrakeSwitchInvalid "Left electric parking brake: a360 ibst brake switch invalid";
CM_ SG_ 968 EPBL_a361_espBrakeSwitchInvalid "Left electric parking brake: a361 esp brake switch invalid";
CM_ SG_ 968 EPBL_a362_ibstPressedEspNotPress "Left electric parking brake: a362 ibst pressed esp not pressed mismatch";
CM_ SG_ 968 EPBL_a363_ibstNotPressedEspPress "Left electric parking brake: a363 ibst not pressed esp pressed mismatch";
CM_ SG_ 968 EPBL_a364_espMasterCylCompOverTh "Left electric parking brake: a364 esp master cyl comp over threshold";
CM_ SG_ 968 EPBL_a365_TooSteepToParkWithTrai "Left electric parking brake: a365 too steep to park with trailer warning";
CM_ SG_ 968 EPBL_a366_TooSteepToParkWithTrai "Left electric parking brake: a366 too steep to park with trailer un sec env";
CM_ SG_ 968 EPBL_a370_imposterDetected "Left electric parking brake: a370 imposter detected";
CM_ SG_ 968 EPBL_a380_canError "Left electric parking brake: a380 can error";
CM_ SG_ 968 EPBL_a381_LIPC_canFault "Left electric parking brake: a381 LIPC can fault";
CM_ SG_ 968 EPBL_a382_CH_canFault "Left electric parking brake: a382 CH can fault";
CM_ BO_ 1992 "Left electric parking brake message: info; frame length observed on a vehicle bus";
CM_ SG_ 1992 EPBL_infoIndex "Left electric parking brake: info index";
CM_ SG_ 1992 EPBL_infoBuildType "Left electric parking brake: info build type";
CM_ SG_ 1992 EPBL_infoBuildConfigId "Left electric parking brake: info build config id";
CM_ SG_ 1992 EPBL_infoHardwareId "Left electric parking brake: info hardware id";
CM_ SG_ 1992 EPBL_infoComponentId "Left electric parking brake: info component id";
CM_ SG_ 1992 EPBL_infoPcbaId "Left electric parking brake: info pcba id";
CM_ SG_ 1992 EPBL_infoAssemblyId "Left electric parking brake: info assembly id; raw 255 = signal not available (SNA)";
CM_ SG_ 1992 EPBL_infoUsageId "Left electric parking brake: info usage id";
CM_ SG_ 1992 EPBL_infoSubUsageId "Left electric parking brake: info sub usage id";
CM_ SG_ 1992 EPBL_infoAppCrc "Left electric parking brake: info app crc";
CM_ SG_ 1992 EPBL_infoAppGitHash "Left electric parking brake: info app git hash";
CM_ SG_ 1992 EPBL_infoBootGitHash "Left electric parking brake: info boot git hash";
CM_ SG_ 1992 EPBL_infoPlatformType "Left electric parking brake: info platform type";
CM_ SG_ 1992 EPBL_infoBootUdsProtoVersion "Left electric parking brake: info boot uds proto version";
CM_ SG_ 1992 EPBL_infoBootCrc "Left electric parking brake: info boot crc";
CM_ BO_ 648 "Left electric parking brake message: internal status; frame length observed on a vehicle bus";
CM_ SG_ 648 EPBL_unitStatus "Electronic Parking Brake's unit state.";
CM_ SG_ 648 EPBL_unitFaultStatus "Left electric parking brake: unit fault status";
CM_ SG_ 648 EPBL_summonState "Left electric parking brake: summon state";
CM_ SG_ 648 EPBL_disconnected "Left electric parking brake: disconnected";
CM_ SG_ 648 EPBL_pistonTouchingRotor "Left electric parking brake: piston touching rotor";
CM_ SG_ 648 EPBL_csmFaultReason "Left electric parking brake: csm fault reason";
CM_ SG_ 648 EPBL_esmOperationTrigger "Left electric parking brake: esm operation trigger";
CM_ SG_ 648 EPBL_summonFaultReason "Error code associated with previous summon failure.";
CM_ SG_ 648 EPBL_localServiceModeActive "Signal reported by Left electric parking brake";
CM_ SG_ 648 EPBL_localCdpState "Left electric parking brake: local cdp state";
CM_ SG_ 648 EPBL_chimeRequestLocal "Left electric parking brake: chime request local";
CM_ SG_ 648 EPBL_telltaleLocal "Left electric parking brake: telltale local; raw 7 = signal not available (SNA)";
CM_ SG_ 648 EPBL_driverIsLeavingLocal "Left electric parking brake: driver is leaving local";
CM_ SG_ 648 EPBL_driverIsLeavingAnySpeedLoca "Left electric parking brake: driver is leaving any speed local";
CM_ SG_ 648 EPBL_internalCDPRequest "Left electric parking brake: internal CDP request";
CM_ SG_ 648 EPBL_esmSpeedClass "Left electric parking brake: esm speed class";
CM_ SG_ 648 EPBL_learnedEpbConfig "Left electric parking brake: learned epb config";
CM_ SG_ 648 EPBL_internalStatusCounter "Left electric parking brake: internal status counter";
CM_ SG_ 648 EPBL_internalStatusChecksum "Left electric parking brake: internal status checksum";
CM_ BO_ 743 "Left electric parking brake message: seat status3; frame length from the layout, not yet observed on a vehicle bus";
CM_ SG_ 743 EPBL_frontSeatCushionFanCur "Left electric parking brake: front seat cushion fan cur";
CM_ SG_ 743 EPBL_frontSeatBackrestFanCur "Left electric parking brake: front seat backrest fan cur";
CM_ SG_ 743 EPBL_frontSeatCushionFanDuty "Left electric parking brake: front seat cushion fan duty";
CM_ SG_ 743 EPBL_frontSeatCushionFanEn "Left electric parking brake: front seat cushion fan en";
CM_ SG_ 743 EPBL_frontSeatBackrestFanEn "Left electric parking brake: front seat backrest fan en";
CM_ SG_ 743 EPBL_frontSeatBackrestFanDuty "Left electric parking brake: front seat backrest fan duty";
CM_ BO_ 680 "Left electric parking brake message: status; frame length observed on a vehicle bus";
CM_ SG_ 680 EPBL_systemStatus "Coordinated state representing the vehicle level parking brake state.";
CM_ SG_ 680 EPBL_freeRollModeStatus "Left electric parking brake: free roll mode status";
CM_ SG_ 680 EPBL_driverIsLeaving "Left electric parking brake: driver is leaving";
CM_ SG_ 680 EPBL_driverIsLeavingAnySpeed "Left electric parking brake: driver is leaving any speed";
CM_ SG_ 680 EPBL_systemCdpAvailable "Left electric parking brake: system cdp available";
CM_ SG_ 680 EPBL_chimeRequest "Left electric parking brake: chime request";
CM_ SG_ 680 EPBL_telltale "Controls the telltale illumination on the instrument cluster; raw 7 = signal not available (SNA)";
CM_ SG_ 680 EPBL_contactorCycleNotNeededForW "Left electric parking brake: contactor cycle not needed for winch entry";
CM_ SG_ 680 EPBL_redundantBrakingEnabled "Left electric parking brake: redundant braking enabled";
CM_ SG_ 680 EPBL_summonEnabled "Left electric parking brake: summon enabled";
CM_ SG_ 680 EPBL_brakeLight "Left electric parking brake: brake light";
CM_ SG_ 680 EPBL_epbConfigMismatch "Left electric parking brake: epb config mismatch";
CM_ SG_ 680 EPBL_brakeConfirmedPressed "Left electric parking brake: brake confirmed pressed";
CM_ SG_ 680 EPBL_requestUserConfirmation "Left electric parking brake: request user confirmation";
CM_ SG_ 680 EPBL_uiWinchModeMiscBlocking "Reports the expected appearance of system error message on User Interface (UI) winch mode panel.";
CM_ SG_ 680 EPBL_winchModeActive "Left electric parking brake: winch mode active";
CM_ SG_ 680 EPBL_updateMode "Left electric parking brake: update mode";
CM_ SG_ 680 EPBL_winchModePermissive "Left electric parking brake: winch mode permissive";
CM_ SG_ 680 EPBL_winchModePending "Left electric parking brake: winch mode pending";
CM_ SG_ 680 EPBL_cdpRequest "Left electric parking brake: cdp request";
CM_ SG_ 680 EPBL_uiParkAvailable "Reports the expected availability and appearance of the park button on User Interface (UI) safety panel.";
CM_ SG_ 680 EPBL_brakeDiscWipeRequest "Left electric parking brake: brake disc wipe request; raw 3 = signal not available (SNA)";
CM_ SG_ 680 EPBL_showUiGearShifter "Left electric parking brake: show ui gear shifter";
CM_ SG_ 680 EPBL_uiWinchModeLvStatus "Reports the expected availability and appearance of Low Voltage (LV) system status on UI winch mode panel.";
CM_ SG_ 680 EPBL_autonomyBehavior "Left electric parking brake: autonomy behavior";
CM_ SG_ 680 EPBL_showStalkFaultedOnUi "Left electric parking brake: show stalk faulted on ui";
CM_ SG_ 680 EPBL_espPowerRequest "Left electric parking brake: esp power request";
CM_ SG_ 680 EPBL_okToPark "Left electric parking brake: ok to park";
CM_ SG_ 680 EPBL_hornRequest "Left electric parking brake: horn request";
CM_ SG_ 680 EPBL_winchModeAvailable "Left electric parking brake: winch mode available";
CM_ SG_ 680 EPBL_bothDisconnected "Left electric parking brake: both disconnected";
CM_ SG_ 680 EPBL_blockDrive "Left electric parking brake: block drive";
CM_ SG_ 680 EPBL_statusCounter "Left electric parking brake: status counter";
CM_ SG_ 680 EPBL_statusChecksum "Left electric parking brake: status checksum";
CM_ BO_ 1573 "Left electric parking brake message: uds response; frame length from the layout, not yet observed on a vehicle bus";
CM_ SG_ 1573 EPBL_udsResponseData_H "Left electric parking brake: uds response data h";
CM_ SG_ 1573 EPBL_udsResponseData_L "Left electric parking brake: uds response data l";
BA_DEF_ BO_ "GenMsgCycleTime" INT 0 3600000;
BA_DEF_ BO_ "GenMsgSendType" ENUM "Cyclic","NotUsed","NotUsed","NotUsed","NotUsed","NotUsed","NotUsed","IfActive","NoMsgSendType","NotUsed";
BA_DEF_ BO_ "VFrameFormat" ENUM "StandardCAN","ExtendedCAN","reserved","J1939PG","reserved","reserved","reserved","reserved","reserved","reserved","reserved","reserved","reserved","reserved","StandardCAN_FD","ExtendedCAN_FD";
BA_DEF_ BO_ "CANFD_BRS" ENUM "0","1";
BA_DEF_ SG_ "GenSigSNA" STRING;
BA_DEF_ SG_ "SystemSignalLongSymbol" STRING;
BA_DEF_ SG_ "Confidence" ENUM "validated","plausible","layout-only","contradicted";
BA_DEF_DEF_ "GenMsgCycleTime" 0;
BA_DEF_DEF_ "GenMsgSendType" "NoMsgSendType";
BA_DEF_DEF_ "VFrameFormat" "StandardCAN";
BA_DEF_DEF_ "CANFD_BRS" "1";
BA_DEF_DEF_ "GenSigSNA" "";
BA_DEF_DEF_ "SystemSignalLongSymbol" "";
BA_DEF_DEF_ "Confidence" "layout-only";
BA_ "GenMsgCycleTime" BO_ 968 100;
BA_ "GenMsgSendType" BO_ 968 0;
BA_ "GenMsgCycleTime" BO_ 1992 1000;
BA_ "GenMsgSendType" BO_ 1992 0;
BA_ "GenMsgCycleTime" BO_ 648 100;
BA_ "GenMsgSendType" BO_ 648 0;
BA_ "GenMsgCycleTime" BO_ 743 1000;
BA_ "GenMsgSendType" BO_ 743 0;
BA_ "GenMsgCycleTime" BO_ 680 100;
BA_ "GenMsgSendType" BO_ 680 0;
BA_ "Confidence" SG_ 968 EPBL_matrixIndex 0;
BA_ "Confidence" SG_ 968 EPBL_a001_WatchdogReset 0;
BA_ "Confidence" SG_ 968 EPBL_a002_PowerLossReset 0;
BA_ "Confidence" SG_ 968 EPBL_a003_SWAssertion 0;
BA_ "Confidence" SG_ 968 EPBL_a005_CANTXError 0;
BA_ "Confidence" SG_ 968 EPBL_a006_CANTX_cyclicError 0;
BA_ "Confidence" SG_ 968 EPBL_a012_CPUReset 0;
BA_ "Confidence" SG_ 968 EPBL_a013_AlertManagerFault 0;
BA_ "Confidence" SG_ 968 EPBL_a015_NVMMError 0;
BA_ "Confidence" SG_ 968 EPBL_a016_NVMMRecordError 0;
BA_ "Confidence" SG_ 968 EPBL_a021_TaskSchedulerError 0;
BA_ "Confidence" SG_ 968 EPBL_a022_TaskInitError 0;
BA_ "Confidence" SG_ 968 EPBL_a029_CoreDump 0;
BA_ "Confidence" SG_ 968 EPBL_a030_ECULogUploadRequest 0;
BA_ "Confidence" SG_ 968 EPBL_a031_UDSActive 0;
BA_ "Confidence" SG_ 968 EPBL_a041_HighCPULoad 0;
BA_ "Confidence" SG_ 968 EPBL_a042_HighStackUsage 0;
BA_ "Confidence" SG_ 968 EPBL_a043_Task1msError 0;
BA_ "Confidence" SG_ 968 EPBL_a044_Task10msError 0;
BA_ "Confidence" SG_ 968 EPBL_a045_Task100msError 0;
BA_ "Confidence" SG_ 968 EPBL_a046_Task1000msError 0;
BA_ "Confidence" SG_ 968 EPBL_a057_HVP_MIA 0;
BA_ "Confidence" SG_ 968 EPBL_a058_inputRHighSyncDebug 0;
BA_ "Confidence" SG_ 968 EPBL_a059_inputResistanceHigh 0;
BA_ "Confidence" SG_ 968 EPBL_a060_engineeringBuild 0;
BA_ "Confidence" SG_ 968 EPBL_a061_XCPConnected 0;
BA_ "Confidence" SG_ 968 EPBL_a062_XCPWasConnected 0;
BA_ "Confidence" SG_ 968 EPBL_a063_SwitchFault 0;
BA_ "Confidence" SG_ 968 EPBL_a064_busSleepReqTimeout 0;
BA_ "Confidence" SG_ 968 EPBL_a081_APP_MIA 0;
BA_ "Confidence" SG_ 968 EPBL_a082_VCRIGHT_IPC_MIA 0;
BA_ "Confidence" SG_ 968 EPBL_a083_VCLEFT_IPC_MIA 0;
BA_ "Confidence" SG_ 968 EPBL_a084_TPMS_MIA 0;
BA_ "Confidence" SG_ 968 EPBL_a085_CCCM_MIA 0;
BA_ "Confidence" SG_ 968 EPBL_a086_VCBATT_MIA 0;
BA_ "Confidence" SG_ 968 EPBL_a087_DIREL_MIA 0;
BA_ "Confidence" SG_ 968 EPBL_a088_DIRER_MIA 0;
BA_ "Confidence" SG_ 968 EPBL_a089_IBST_MIA 0;
BA_ "Confidence" SG_ 968 EPBL_a090_APS_MIA 0;
BA_ "Confidence" SG_ 968 EPBL_a091_CMPD_MIA 0;
BA_ "Confidence" SG_ 968 EPBL_a092_VCSEATD_MIA 0;
BA_ "Confidence" SG_ 968 EPBL_a093_VCSEATP_MIA 0;
BA_ "Confidence" SG_ 968 EPBL_a094_EPAS3P_MIA 0;
BA_ "Confidence" SG_ 968 EPBL_a095_CHG_MIA 0;
BA_ "Confidence" SG_ 968 EPBL_a096_OCS1P_MIA 0;
BA_ "Confidence" SG_ 968 EPBL_a097_CMP_MIA 0;
BA_ "Confidence" SG_ 968 EPBL_a098_DIR_MIA 0;
BA_ "Confidence" SG_ 968 EPBL_a099_PARK_MIA 0;
BA_ "Confidence" SG_ 968 EPBL_a100_CANbus_MIA 0;
BA_ "Confidence" SG_ 968 EPBL_a101_PM_MIA 0;
BA_ "Confidence" SG_ 968 EPBL_a102_PTC_MIA 0;
BA_ "Confidence" SG_ 968 EPBL_a103_CP_MIA 0;
BA_ "Confidence" SG_ 968 EPBL_a104_DAS_MIA 0;
BA_ "Confidence" SG_ 968 EPBL_a105_TAS_MIA 0;
BA_ "Confidence" SG_ 968 EPBL_a106_PCS_MIA 0;
BA_ "Confidence" SG_ 968 EPBL_a107_BMS_MIA 0;
BA_ "Confidence" SG_ 968 EPBL_a108_DIF_MIA 0;
BA_ "Confidence" SG_ 968 EPBL_a109_RCM_MIA 0;
BA_ "Confidence" SG_ 968 EPBL_a110_GTW_MIA 0;
BA_ "Confidence" SG_ 968 EPBL_a111_EPBR_MIA 0;
BA_ "Confidence" SG_ 968 EPBL_a112_EPBL_MIA 0;
BA_ "Confidence" SG_ 968 EPBL_a113_UI_MIA 0;
BA_ "Confidence" SG_ 968 EPBL_a114_ESP_MIA 0;
BA_ "Confidence" SG_ 968 EPBL_a115_VCSEC_MIA 0;
BA_ "Confidence" SG_ 968 EPBL_a116_VCRIGHT_MIA 0;
BA_ "Confidence" SG_ 968 EPBL_a117_VCLEFT_MIA 0;
BA_ "Confidence" SG_ 968 EPBL_a118_VCFRONT_MIA 0;
BA_ "Confidence" SG_ 968 EPBL_a119_SCCM_MIA 0;
BA_ "Confidence" SG_ 968 EPBL_a120_DI_DRIVE_MIA 0;
BA_ "Confidence" SG_ 968 EPBL_a121_nDriveFault 0;
BA_ "Confidence" SG_ 968 EPBL_a122_Oc 0;
BA_ "Confidence" SG_ 968 EPBL_a123_Uc 0;
BA_ "Confidence" SG_ 968 EPBL_a124_calOutOfBounds 0;
BA_ "Confidence" SG_ 968 EPBL_a125_IdleVMismatch 0;
BA_ "Confidence" SG_ 968 EPBL_a126_MotorNVoltLow 0;
BA_ "Confidence" SG_ 968 EPBL_a127_MotorNVoltHigh 0;
BA_ "Confidence" SG_ 968 EPBL_a128_MotorPVoltHigh 0;
BA_ "Confidence" SG_ 968 EPBL_a129_ICR_MIA 0;
BA_ "Confidence" SG_ 968 EPBL_a130_BB_MIA 0;
BA_ "Confidence" SG_ 968 EPBL_a131_RCU_MIA 0;
BA_ "Confidence" SG_ 968 EPBL_a132_VCBATT1_MIA 0;
BA_ "Confidence" SG_ 968 EPBL_a133_VCBATT2_MIA 0;
BA_ "Confidence" SG_ 968 EPBL_a134_NvOv 0;
BA_ "Confidence" SG_ 968 EPBL_a135_NvUv 0;
BA_ "Confidence" SG_ 968 EPBL_a136_PvOv 0;
BA_ "Confidence" SG_ 968 EPBL_a137_PvUv 0;
BA_ "Confidence" SG_ 968 EPBL_a138_NvmDualFailure 0;
BA_ "Confidence" SG_ 968 EPBL_a139_NvmRedundancyLoss 0;
BA_ "Confidence" SG_ 968 EPBL_a140_NvmSlowWrite 0;
BA_ "Confidence" SG_ 968 EPBL_a141_invalidState 0;
BA_ "Confidence" SG_ 968 EPBL_a170_12vOv 0;
BA_ "Confidence" SG_ 968 EPBL_a171_12vUv 0;
BA_ "Confidence" SG_ 968 EPBL_a172_SPI_MIA 0;
BA_ "Confidence" SG_ 968 EPBL_a173_hiCurrentMissing 0;
BA_ "Confidence" SG_ 968 EPBL_a174_csmReleaseFailed 0;
BA_ "Confidence" SG_ 968 EPBL_a175_csmReleaseRetry 0;
BA_ "Confidence" SG_ 968 EPBL_a176_csmApplyFailed 0;
BA_ "Confidence" SG_ 968 EPBL_a177_csmApplyRetry 0;
BA_ "Confidence" SG_ 968 EPBL_a178_caliperStateUnknown 0;
BA_ "Confidence" SG_ 968 EPBL_a179_epbProblem 0;
BA_ "Confidence" SG_ 968 EPBL_a180_dynamicActive 0;
BA_ "Confidence" SG_ 968 EPBL_a181_TooSteepGradeToPark 0;
BA_ "Confidence" SG_ 968 EPBL_a182_OneEPBAppliedUnsecEnv 0;
BA_ "Confidence" SG_ 968 EPBL_a183_cdpNotAvailable 0;
BA_ "Confidence" SG_ 968 EPBL_a184_dynamicParkAbort 0;
BA_ "Confidence" SG_ 968 EPBL_a185_summonAborted 0;
BA_ "Confidence" SG_ 968 EPBL_a186_externalParkAbort 0;
BA_ "Confidence" SG_ 968 EPBL_a187_cdpDynamic 0;
BA_ "Confidence" SG_ 968 EPBL_a188_epbDynamic 0;
BA_ "Confidence" SG_ 968 EPBL_a189_epbDynamicParkCanceled 0;
BA_ "Confidence" SG_ 968 EPBL_a190_csmApplyDegraded 0;
BA_ "Confidence" SG_ 968 EPBL_a191_csmReleaseDegraded 0;
BA_ "Confidence" SG_ 968 EPBL_a195_parkForDriverIsLeaving 0;
BA_ "Confidence" SG_ 968 EPBL_a196_freeRollModeActive 0;
BA_ "Confidence" SG_ 968 EPBL_a197_freeRollModeAtSpeed 0;
BA_ "Confidence" SG_ 968 EPBL_a198_holdClampComplete 0;
BA_ "Confidence" SG_ 968 EPBL_a200_PmUnparkNotAllowed 0;
BA_ "Confidence" SG_ 968 EPBL_a202_remoteEpbConfigIncompa 0;
BA_ "SystemSignalLongSymbol" SG_ 968 EPBL_a202_remoteEpbConfigIncompa "EPBL_a202_remoteEpbConfigIncompatible";
BA_ "Confidence" SG_ 968 EPBL_a203_hwBrakeTypeMismatch 0;
BA_ "Confidence" SG_ 968 EPBL_a210_parkForDriverIsLeaving 0;
BA_ "SystemSignalLongSymbol" SG_ 968 EPBL_a210_parkForDriverIsLeaving "EPBL_a210_parkForDriverIsLeavingDebug";
BA_ "Confidence" SG_ 968 EPBL_a216_SPI_MIA_debugData1 0;
BA_ "Confidence" SG_ 968 EPBL_a217_SPI_MIA_debugData2 0;
BA_ "Confidence" SG_ 968 EPBL_a225_epbActiveDecel 0;
BA_ "Confidence" SG_ 968 EPBL_a241_diOutputLocked 0;
BA_ "Confidence" SG_ 968 EPBL_a242_hvOutputLocked 0;
BA_ "Confidence" SG_ 968 EPBL_a243_bdwUnavailable 0;
BA_ "Confidence" SG_ 968 EPBL_a244_WinchModeActive 0;
BA_ "Confidence" SG_ 968 EPBL_a245_serviceModeActive 0;
BA_ "Confidence" SG_ 968 EPBL_a246_idleFaultApply 0;
BA_ "Confidence" SG_ 968 EPBL_a247_csmDynamicApplyRetry 0;
BA_ "Confidence" SG_ 968 EPBL_a248_csmDynamicApplyFailed 0;
BA_ "Confidence" SG_ 968 EPBL_a249_idleFaultRelease 0;
BA_ "Confidence" SG_ 968 EPBL_a250_WinchModeCanceled 0;
BA_ "Confidence" SG_ 968 EPBL_a251_currentVarianceHigh 0;
BA_ "Confidence" SG_ 968 EPBL_a252_winchModePending 0;
BA_ "Confidence" SG_ 968 EPBL_a253_esmReleaseBlocked 0;
BA_ "Confidence" SG_ 968 EPBL_a254_showStalkParkButtonFau 0;
BA_ "SystemSignalLongSymbol" SG_ 968 EPBL_a254_showStalkParkButtonFau "EPBL_a254_showStalkParkButtonFaultOnUi";
BA_ "Confidence" SG_ 968 EPBL_a256_epbSystemApply 0;
BA_ "Confidence" SG_ 968 EPBL_a261_winchModeWithoutSteeri 0;
BA_ "SystemSignalLongSymbol" SG_ 968 EPBL_a261_winchModeWithoutSteeri "EPBL_a261_winchModeWithoutSteering";
BA_ "Confidence" SG_ 968 EPBL_a262_cannotPrepareWinchMode 0;
BA_ "Confidence" SG_ 968 EPBL_a263_epbRecoveryPark 0;
BA_ "Confidence" SG_ 968 EPBL_a264_winchModeDeactivated 0;
BA_ "Confidence" SG_ 968 EPBL_a272_vhclPwrStateMsmtch 0;
BA_ "Confidence" SG_ 968 EPBL_a300_leftRightConfusion 0;
BA_ "Confidence" SG_ 968 EPBL_a301_oocSpeedViolation 0;
BA_ "Confidence" SG_ 968 EPBL_a302_csmLongRelease 0;
BA_ "Confidence" SG_ 968 EPBL_a303_clampingOccuredEarly 0;
BA_ "Confidence" SG_ 968 EPBL_a304_rearSeatControllerEFus 0;
BA_ "SystemSignalLongSymbol" SG_ 968 EPBL_a304_rearSeatControllerEFus "EPBL_a304_rearSeatControllerEFuseTrip";
BA_ "Confidence" SG_ 968 EPBL_a305_premiumAmpEFuseTrip 0;
BA_ "Confidence" SG_ 968 EPBL_a330_parkForApIsLeaving 0;
BA_ "Confidence" SG_ 968 EPBL_a350_ensOutOfRange 0;
BA_ "Confidence" SG_ 968 EPBL_a352_audioCurrentSpikeData 0;
BA_ "Confidence" SG_ 968 EPBL_a353_missingSpeedUnableToPa 0;
BA_ "SystemSignalLongSymbol" SG_ 968 EPBL_a353_missingSpeedUnableToPa "EPBL_a353_missingSpeedUnableToPark";
BA_ "Confidence" SG_ 968 EPBL_a354_parkedForLowBrakeFluid 0;
BA_ "SystemSignalLongSymbol" SG_ 968 EPBL_a354_parkedForLowBrakeFluid "EPBL_a354_parkedForLowBrakeFluidMode";
BA_ "Confidence" SG_ 968 EPBL_a355_brakeHwAndEpbHwMismatc 0;
BA_ "SystemSignalLongSymbol" SG_ 968 EPBL_a355_brakeHwAndEpbHwMismatc "EPBL_a355_brakeHwAndEpbHwMismatch";
BA_ "Confidence" SG_ 968 EPBL_a356_parkingForStationaryDe 0;
BA_ "SystemSignalLongSymbol" SG_ 968 EPBL_a356_parkingForStationaryDe "EPBL_a356_parkingForStationaryDetect";
BA_ "Confidence" SG_ 968 EPBL_a357_brakesTooHotForSlope 0;
BA_ "Confidence" SG_ 968 EPBL_a358_brakesTooHotForSlopeWi 0;
BA_ "SystemSignalLongSymbol" SG_ 968 EPBL_a358_brakesTooHotForSlopeWi "EPBL_a358_brakesTooHotForSlopeWithOnlyOneEpb";
BA_ "Confidence" SG_ 968 EPBL_a360_ibstBrakeSwitchInvalid 0;
BA_ "Confidence" SG_ 968 EPBL_a361_espBrakeSwitchInvalid 0;
BA_ "Confidence" SG_ 968 EPBL_a362_ibstPressedEspNotPress 0;
BA_ "SystemSignalLongSymbol" SG_ 968 EPBL_a362_ibstPressedEspNotPress "EPBL_a362_ibstPressedEspNotPressedMismatch";
BA_ "Confidence" SG_ 968 EPBL_a363_ibstNotPressedEspPress 0;
BA_ "SystemSignalLongSymbol" SG_ 968 EPBL_a363_ibstNotPressedEspPress "EPBL_a363_ibstNotPressedEspPressedMismatch";
BA_ "Confidence" SG_ 968 EPBL_a364_espMasterCylCompOverTh 0;
BA_ "SystemSignalLongSymbol" SG_ 968 EPBL_a364_espMasterCylCompOverTh "EPBL_a364_espMasterCylCompOverThreshold";
BA_ "Confidence" SG_ 968 EPBL_a365_TooSteepToParkWithTrai 0;
BA_ "SystemSignalLongSymbol" SG_ 968 EPBL_a365_TooSteepToParkWithTrai "EPBL_a365_TooSteepToParkWithTrailerWarning";
BA_ "Confidence" SG_ 968 EPBL_a366_TooSteepToParkWithTrai 0;
BA_ "SystemSignalLongSymbol" SG_ 968 EPBL_a366_TooSteepToParkWithTrai "EPBL_a366_TooSteepToParkWithTrailerUnSecEnv";
BA_ "Confidence" SG_ 968 EPBL_a370_imposterDetected 0;
BA_ "Confidence" SG_ 968 EPBL_a380_canError 0;
BA_ "Confidence" SG_ 968 EPBL_a381_LIPC_canFault 0;
BA_ "Confidence" SG_ 968 EPBL_a382_CH_canFault 0;
BA_ "Confidence" SG_ 1992 EPBL_infoIndex 0;
BA_ "Confidence" SG_ 1992 EPBL_infoBuildType 0;
BA_ "Confidence" SG_ 1992 EPBL_infoBuildConfigId 0;
BA_ "Confidence" SG_ 1992 EPBL_infoHardwareId 0;
BA_ "Confidence" SG_ 1992 EPBL_infoComponentId 0;
BA_ "Confidence" SG_ 1992 EPBL_infoPcbaId 0;
BA_ "Confidence" SG_ 1992 EPBL_infoAssemblyId 0;
BA_ "GenSigSNA" SG_ 1992 EPBL_infoAssemblyId "255";
BA_ "Confidence" SG_ 1992 EPBL_infoUsageId 0;
BA_ "Confidence" SG_ 1992 EPBL_infoSubUsageId 0;
BA_ "Confidence" SG_ 1992 EPBL_infoAppCrc 0;
BA_ "Confidence" SG_ 1992 EPBL_infoAppGitHash 0;
BA_ "Confidence" SG_ 1992 EPBL_infoBootGitHash 0;
BA_ "Confidence" SG_ 1992 EPBL_infoPlatformType 0;
BA_ "Confidence" SG_ 1992 EPBL_infoBootUdsProtoVersion 0;
BA_ "Confidence" SG_ 1992 EPBL_infoBootCrc 0;
BA_ "Confidence" SG_ 648 EPBL_unitStatus 0;
BA_ "Confidence" SG_ 648 EPBL_unitFaultStatus 0;
BA_ "Confidence" SG_ 648 EPBL_summonState 0;
BA_ "Confidence" SG_ 648 EPBL_disconnected 0;
BA_ "Confidence" SG_ 648 EPBL_pistonTouchingRotor 0;
BA_ "Confidence" SG_ 648 EPBL_csmFaultReason 0;
BA_ "Confidence" SG_ 648 EPBL_esmOperationTrigger 0;
BA_ "Confidence" SG_ 648 EPBL_summonFaultReason 0;
BA_ "Confidence" SG_ 648 EPBL_localServiceModeActive 0;
BA_ "Confidence" SG_ 648 EPBL_localCdpState 0;
BA_ "Confidence" SG_ 648 EPBL_chimeRequestLocal 0;
BA_ "Confidence" SG_ 648 EPBL_telltaleLocal 0;
BA_ "GenSigSNA" SG_ 648 EPBL_telltaleLocal "7";
BA_ "Confidence" SG_ 648 EPBL_driverIsLeavingLocal 0;
BA_ "Confidence" SG_ 648 EPBL_driverIsLeavingAnySpeedLoca 0;
BA_ "SystemSignalLongSymbol" SG_ 648 EPBL_driverIsLeavingAnySpeedLoca "EPBL_driverIsLeavingAnySpeedLocal";
BA_ "Confidence" SG_ 648 EPBL_internalCDPRequest 0;
BA_ "Confidence" SG_ 648 EPBL_esmSpeedClass 0;
BA_ "Confidence" SG_ 648 EPBL_learnedEpbConfig 0;
BA_ "Confidence" SG_ 648 EPBL_internalStatusCounter 0;
BA_ "Confidence" SG_ 648 EPBL_internalStatusChecksum 0;
BA_ "Confidence" SG_ 743 EPBL_frontSeatCushionFanCur 0;
BA_ "Confidence" SG_ 743 EPBL_frontSeatBackrestFanCur 0;
BA_ "Confidence" SG_ 743 EPBL_frontSeatCushionFanDuty 0;
BA_ "Confidence" SG_ 743 EPBL_frontSeatCushionFanEn 0;
BA_ "Confidence" SG_ 743 EPBL_frontSeatBackrestFanEn 0;
BA_ "Confidence" SG_ 743 EPBL_frontSeatBackrestFanDuty 0;
BA_ "Confidence" SG_ 680 EPBL_systemStatus 0;
BA_ "Confidence" SG_ 680 EPBL_freeRollModeStatus 0;
BA_ "Confidence" SG_ 680 EPBL_driverIsLeaving 0;
BA_ "Confidence" SG_ 680 EPBL_driverIsLeavingAnySpeed 0;
BA_ "Confidence" SG_ 680 EPBL_systemCdpAvailable 0;
BA_ "Confidence" SG_ 680 EPBL_chimeRequest 0;
BA_ "Confidence" SG_ 680 EPBL_telltale 0;
BA_ "GenSigSNA" SG_ 680 EPBL_telltale "7";
BA_ "Confidence" SG_ 680 EPBL_contactorCycleNotNeededForW 0;
BA_ "SystemSignalLongSymbol" SG_ 680 EPBL_contactorCycleNotNeededForW "EPBL_contactorCycleNotNeededForWinchEntry";
BA_ "Confidence" SG_ 680 EPBL_redundantBrakingEnabled 0;
BA_ "Confidence" SG_ 680 EPBL_summonEnabled 0;
BA_ "Confidence" SG_ 680 EPBL_brakeLight 0;
BA_ "Confidence" SG_ 680 EPBL_epbConfigMismatch 0;
BA_ "Confidence" SG_ 680 EPBL_brakeConfirmedPressed 0;
BA_ "Confidence" SG_ 680 EPBL_requestUserConfirmation 0;
BA_ "Confidence" SG_ 680 EPBL_uiWinchModeMiscBlocking 0;
BA_ "Confidence" SG_ 680 EPBL_winchModeActive 0;
BA_ "Confidence" SG_ 680 EPBL_updateMode 0;
BA_ "Confidence" SG_ 680 EPBL_winchModePermissive 0;
BA_ "Confidence" SG_ 680 EPBL_winchModePending 0;
BA_ "Confidence" SG_ 680 EPBL_cdpRequest 0;
BA_ "Confidence" SG_ 680 EPBL_uiParkAvailable 0;
BA_ "Confidence" SG_ 680 EPBL_brakeDiscWipeRequest 0;
BA_ "GenSigSNA" SG_ 680 EPBL_brakeDiscWipeRequest "3";
BA_ "Confidence" SG_ 680 EPBL_showUiGearShifter 0;
BA_ "Confidence" SG_ 680 EPBL_uiWinchModeLvStatus 0;
BA_ "Confidence" SG_ 680 EPBL_autonomyBehavior 0;
BA_ "Confidence" SG_ 680 EPBL_showStalkFaultedOnUi 0;
BA_ "Confidence" SG_ 680 EPBL_espPowerRequest 0;
BA_ "Confidence" SG_ 680 EPBL_okToPark 0;
BA_ "Confidence" SG_ 680 EPBL_hornRequest 0;
BA_ "Confidence" SG_ 680 EPBL_winchModeAvailable 0;
BA_ "Confidence" SG_ 680 EPBL_bothDisconnected 0;
BA_ "Confidence" SG_ 680 EPBL_blockDrive 0;
BA_ "Confidence" SG_ 680 EPBL_statusCounter 0;
BA_ "Confidence" SG_ 680 EPBL_statusChecksum 0;
BA_ "Confidence" SG_ 1573 EPBL_udsResponseData_H 1;
BA_ "Confidence" SG_ 1573 EPBL_udsResponseData_L 1;
VAL_ 968 EPBL_matrixIndex 6 "AlertMatrix6" 5 "AlertMatrix5" 4 "AlertMatrix4" 3 "AlertMatrix3" 2 "AlertMatrix2" 1 "AlertMatrix1" 0 "AlertMatrix0" ;
VAL_ 1992 EPBL_infoIndex 255 "END" 41 "SUBCOMPONENT14" 40 "SUBCOMPONENT13" 39 "SUBCOMPONENT12" 38 "SUBCOMPONENT11" 37 "SUBCOMPONENT10" 36 "SUBCOMPONENT9" 35 "SUBCOMPONENT8" 34 "SUBCOMPONENT7" 33 "SUBCOMPONENT6" 32 "SUBCOMPONENT5" 31 "SUBCOMPONENT4" 24 "SUBCOMPONENT3" 23 "SUBCOMPONENT2" 20 "UDS_PROTOCOL_BOOTCRC" 19 "VERSION_DEPRECATED" 18 "BOOTLOADER_GITHASH" 17 "APP_GITHASH" 16 "SUBCOMPONENT1" 15 "BOOTLOADER_CRC" 14 "BOOTLOADER_SVN" 13 "APP_CRC" 11 "PCBAID_ASSYID_USAGEID" 10 "BUILD_HWID_COMPONENTID" 9 "DEPRECATED_9" 8 "DEPRECATED_8" 7 "DEPRECATED_7" 6 "DEPRECATED_6" 5 "DEPRECATED_5" 4 "DEPRECATED_4" 3 "DEPRECATED_3" 2 "DEPRECATED_2" 1 "DEPRECATED_1" 0 "DEPRECATED_0" ;
VAL_ 1992 EPBL_infoBuildType 4 "INFO_MFG_BUILD" 3 "INFO_TRACEABLE_CI_BUILD" 2 "INFO_LOCAL_BUILD" 1 "INFO_PLATFORM_BUILD" 0 "INFO_UNKNOWN_BUILD" ;
VAL_ 1992 EPBL_infoAssemblyId 255 "ASSEMBLY_SNA" 1 "ASSEMBLY1" ;
VAL_ 648 EPBL_unitStatus 23 "EPB_STATUS_COUNT" 22 "EPB_STATUS_AUTONOMY_OPEN" 21 "EPB_STATUS_FREE_ROLL_MODE" 20 "EPB_STATUS_DYNAMIC_PARKING" 19 "EPB_STATUS_EXTERNAL_PARKING" 18 "EPB_STATUS_RELEASING_FOR_EXTERNAL_PARK" 17 "EPB_STATUS_EXTERNAL_DYNAMIC" 16 "EPB_STATUS_SUMMON_PARKING" 15 "EPB_STATUS_SUMMON_RELEASING" 14 "EPB_STATUS_SUMMON" 13 "EPB_STATUS_WINCHMODE_PENDING" 12 "EPB_STATUS_PARK_PENDING" 11 "EPB_STATUS_SERVICE_RELEASING" 10 "EPB_STATUS_RELEASING" 9 "EPB_STATUS_DYNAMIC_APPLYING" 8 "EPB_STATUS_PARKING" 7 "EPB_STATUS_WINCHMODE_RELEASING" 6 "EPB_STATUS_WINCHMODE" 5 "EPB_STATUS_SERVICE" 4 "EPB_STATUS_START" 3 "EPB_STATUS_PARK" 2 "EPB_STATUS_DYNAMIC" 1 "EPB_STATUS_OPEN" 0 "EPB_STATUS_UNKNOWN" ;
VAL_ 648 EPBL_unitFaultStatus 3 "EPB_STATUS_FAULT_IDLE" 2 "EPB_STATUS_FAULT" 1 "EPB_STATUS_RETRY" 0 "EPB_STATUS_NOMINAL" ;
VAL_ 648 EPBL_summonState 6 "EPB_SUMMON_UNAVAILABLE" 5 "EPB_SUMMON_FAULT" 4 "EPB_SUMMON_COMPLETE" 3 "EPB_SUMMON_ACTIVE" 2 "EPB_SUMMON_ARMED" 1 "EPB_SUMMON_IDLE" 0 "EPB_SUMMON_INIT" ;
VAL_ 648 EPBL_csmFaultReason 23 "CSM_FAULT_REMOTE_MIA" 22 "CSM_FAULT_NVM_MISMATCH" 21 "CSM_FAULT_EPBM_MIA" 20 "CSM_FAULT_MOTOR_NOT_READY" 19 "CSM_FAULT_MOTOR_ACTIVE_FAULT" 18 "CSM_FAULT_MOTOR_IDLE_FAULT" 17 "CSM_FAULT_TIMEOUT_EPBM_START" 16 "CSM_FAULT_TIMEOUT_NO_RAMP" 15 "CSM_FAULT_TIMEOUT_EPBM_CUTOFF" 14 "CSM_FAULT_TIMEOUT_RELEASE_COMPLETE" 13 "CSM_FAULT_TIMEOUT_RELEASE_NO_LOAD" 12 "CSM_FAULT_TIMEOUT_RELEASE_WAIT_FOR_ENDSTOP" 11 "CSM_FAULT_TIMEOUT_RELEASE_INRUSH" 10 "CSM_FAULT_TIMEOUT_EPBM_WAIT_FOR_CLAMP" 9 "CSM_FAULT_TIMEOUT_EPB_WAIT_FOR_CLAMP" 8 "CSM_FAULT_TIMEOUT_APPLY_INRUSH" 7 "CSM_FAULT_TIMEOUT_APPLY_COMPLETE" 6 "CSM_FAULT_RELEASE_BLOCKED" 5 "CSM_FAULT_APPLY_BLOCKED" 4 "CSM_FAULT_TIMEOUT_CALIBRATE" 3 "CSM_FAULT_STATE_MISMATCH" 2 "CSM_FAULT_EPBM_FAULTED" 1 "CSM_FAULT_EPBM_DISABLED" 0 "CSM_FAULT_NONE" ;
VAL_ 648 EPBL_esmOperationTrigger 50 "EPB_TRIGGER_ACTIVE_DECEL_DAS_STATIC" 49 "EPB_TRIGGER_ACTIVE_DECEL_CDP_DOWN" 48 "EPB_TRIGGER_AP_IS_LEAVING" 47 "EPB_TRIGGER_RECOVERY_PARK" 46 "EPB_TRIGGER_SPEED_SOURCES_LOST" 45 "EPB_TRIGGER_ACTIVE_DECEL_OKTOPARK" 44 "EPB_TRIGGER_ACTIVE_DECEL_FAST" 43 "EPB_TRIGGER_STEERING_ACTIVE_DECEL" 42 "EPB_TRIGGER_LV_ACTIVE_DECEL" 41 "EPB_TRIGGER_CDP_PANIC_MODE_READY" 40 "EPB_TRIGGER_CDP_PANIC_MODE_TIMEOUT" 39 "EPB_TRIGGER_DI_PARK" 38 "EPB_TRIGGER_FREE_ROLL_PARK_FOR_HANDLE_PULLED" 37 "EPB_TRIGGER_LOW_BRAKE_FLUID_MODE_DYNAMIC" 36 "EPB_TRIGGER_LOW_BRAKE_FLUID_MODE_DYNAMIC_PARK" 35 "EPB_TRIGGER_LOW_BRAKE_FLUID_MODE_PARK" 34 "EPB_TRIGGER_STATIONARY_DETECT" 33 "EPB_TRIGGER_TOUCHSCREEN_INVALID" 32 "EPB_TRIGGER_UI_DOOR_OPEN_REQUEST" 31 "EPB_TRIGGER_AUTOPARK_END" 30 "EPB_TRIGGER_DRIVER_IS_LEAVING" 29 "EPB_TRIGGER_SYSTEM_APPLY" 28 "EPB_TRIGGER_ACCELERATION" 27 "EPB_TRIGGER_EPBM_DISQUALIFIED" 26 "EPB_TRIGGER_DISQUALIFIED" 25 "EPB_TRIGGER_SUMMON_FAULT" 24 "EPB_TRIGGER_FAULT" 23 "EPB_TRIGGER_SUMMON_COMPLETE" 22 "EPB_TRIGGER_REAPPLY" 21 "EPB_TRIGGER_SAVESTATE_ON_BOOT" 20 "EPB_TRIGGER_TIMEOUT" 19 "EPB_TRIGGER_SPEED_FAST" 18 "EPB_TRIGGER_SPEED_OKAYTOPARK" 17 "EPB_TRIGGER_SPEED_STOPPED" 16 "EPB_TRIGGER_USER_CANCEL" 15 "EPB_TRIGGER_USER_CONFIRMED" 14 "EPB_TRIGGER_DIAG_EXIT" 13 "EPB_TRIGGER_DIAG_OPEN" 12 "EPB_TRIGGER_DIAG_CLOSE" 11 "EPB_TRIGGER_SERVICE" 10 "EPB_TRIGGER_WINCHMODE_UNAVAILABLE" 9 "EPB_TRIGGER_WINCHMODE_ENTER" 8 "EPB_TRIGGER_WINCHMODE_EXIT" 7 "EPB_TRIGGER_TOUCHSCREEN" 6 "EPB_TRIGGER_DI_UNPARK" 5 "EPB_TRIGGER_ACTIVE_PARK_REQUEST" 4 "EPB_TRIGGER_PBUTTON_RELEASED" 3 "EPB_TRIGGER_PBUTTON_PRESSED_UNKNOWN" 2 "EPB_TRIGGER_PBUTTON_PRESSED_FAST" 1 "EPB_TRIGGER_PBUTTON_PRESSED_OKTOPARK" 0 "EPB_TRIGGER_PBUTTON_PRESSED_STOPPED" ;
VAL_ 648 EPBL_summonFaultReason 30 "EPB_SUMMONFAULT_MONITOR_TYPE_UNKNOWN" 29 "EPB_SUMMONFAULT_AP_MONITOR" 28 "EPB_SUMMONFAULT_REMOTE_DID_NOT_START" 27 "EPB_SUMMONFAULT_INVALID_REMOTE_STATE" 26 "EPB_SUMMONFAULT_START_IN_UNAVAILABLE" 25 "EPB_SUMMONFAULT_REMOTE_UNIT_FAULTED" 24 "EPB_SUMMONFAULT_LOCAL_UNIT_FAULTED" 23 "EPB_SUMMONFAULT_REMOTE_SUMMON_FAULTED" 22 "EPB_SUMMONFAULT_EPBREMOTE_MIA" 21 "EPB_SUMMONFAULT_PASSIVE_REQUEST" 20 "EPB_SUMMONFAULT_DI_STATE_INVALID" 19 "EPB_SUMMONFAULT_EPB_FAULT" 18 "EPB_SUMMONFAULT_MISMATCH" 17 "EPB_SUMMONFAULT_OOC" 16 "EPB_SUMMONFAULT_PM_REQUEST" 15 "EPB_SUMMONFAULT_PM_MIA" 14 "EPB_SUMMONFAULT_PARK_MIA" 13 "EPB_SUMMONFAULT_EXTERNAL" 12 "EPB_SUMMONFAULT_SPEED" 11 "EPB_SUMMONFAULT_EPBM_REQUEST" 10 "EPB_SUMMONFAULT_EAC_NOT_ALLOWED" 9 "EPB_SUMMONFAULT_VEH_CAN_FAULT" 8 "EPB_SUMMONFAULT_ESP_FAULT" 7 "EPB_SUMMONFAULT_DAS_FAULT" 6 "EPB_SUMMONFAULT_DI_APC_FAULT" 5 "EPB_SUMMONFAULT_DI_FAULT" 4 "EPB_SUMMONFAULT_EPBM_MIA" 3 "EPB_SUMMONFAULT_ESP_MIA" 2 "EPB_SUMMONFAULT_DAS_MIA" 1 "EPB_SUMMONFAULT_DI_MIA" 0 "EPB_SUMMONFAULT_NONE" ;
VAL_ 648 EPBL_localCdpState 2 "EPB_CDP_STATE_FAULT" 1 "EPB_CDP_STATE_VALID" 0 "EPB_CDP_STATE_UNKNOWN" ;
VAL_ 648 EPBL_chimeRequestLocal 4 "EPB_CHIME_REQUEST_ACTIVE_DECEL" 3 "EPB_CHIME_REQUEST_ABOUT_TO_ACTIVE_DECEL" 2 "EPB_CHIME_REQUEST_GPO" 1 "EPB_CHIME_REQUEST_GENERAL" 0 "EPB_CHIME_REQUEST_NONE" ;
VAL_ 648 EPBL_telltaleLocal 7 "EPB_TELLTALE_SNA" 4 "EPB_TELLTALE_LAMP_RED_FLASH" 3 "EPB_TELLTALE_LAMP_AMBER_ON" 2 "EPB_TELLTALE_LAMP_RED_ON" 1 "EPB_TELLTALE_LAMP_RED_PARKED" 0 "EPB_TELLTALE_LAMP_OFF" ;
VAL_ 648 EPBL_internalCDPRequest 1 "EPB_CDP_REQUESTED" 0 "EPB_CDP_NOT_REQUESTED" ;
VAL_ 648 EPBL_esmSpeedClass 4 "ESM_SPEED_CLASS_UNKNOWN" 3 "ESM_SPEED_CLASS_FAST" 2 "ESM_SPEED_CLASS_USER_APPLY_OK" 1 "ESM_SPEED_CLASS_SYSTEM_APPLY_OK" 0 "ESM_SPEED_CLASS_STOPPED" ;
VAL_ 648 EPBL_learnedEpbConfig 11 "EPB_CONFIG_CT_MANDO" 10 "EPB_CONFIG_MODEL3_ZF" 9 "EPB_CONFIG_MODELS_CERAMIC" 8 "EPB_CONFIG_MODELY_PERFORMANCE_V2" 7 "EPB_CONFIG_MODEL3_PERFORMANCE_V2" 6 "EPB_CONFIG_MODELX_BASE" 5 "EPB_CONFIG_MODELY_PERFORMANCE" 4 "EPB_CONFIG_MODELY_BASE" 3 "EPB_CONFIG_MODELS_BASE" 2 "EPB_CONFIG_MODEL3_PERFORMANCE" 1 "EPB_CONFIG_MODEL3_BASE" 0 "EPB_CONFIG_UNKNOWN" ;
VAL_ 680 EPBL_systemStatus 8 "EPB_VEHICLE_STATUS_MISMATCH" 7 "EPB_VEHICLE_STATUS_FAULT_SECURE" 6 "EPB_VEHICLE_STATUS_FAULT" 5 "EPB_VEHICLE_STATUS_RELEASING" 4 "EPB_VEHICLE_STATUS_PARKING" 3 "EPB_VEHICLE_STATUS_DYNAMIC" 2 "EPB_VEHICLE_STATUS_PARKED" 1 "EPB_VEHICLE_STATUS_RELEASED" 0 "EPB_VEHICLE_STATUS_UNKNOWN" ;
VAL_ 680 EPBL_freeRollModeStatus 2 "EPB_FREE_ROLL_MODE_ENABLED" 1 "EPB_FREE_ROLL_MODE_AVAILABLE" 0 "EPB_FREE_ROLL_MODE_UNAVAILABLE" ;
VAL_ 680 EPBL_chimeRequest 4 "EPB_CHIME_REQUEST_ACTIVE_DECEL" 3 "EPB_CHIME_REQUEST_ABOUT_TO_ACTIVE_DECEL" 2 "EPB_CHIME_REQUEST_GPO" 1 "EPB_CHIME_REQUEST_GENERAL" 0 "EPB_CHIME_REQUEST_NONE" ;
VAL_ 680 EPBL_telltale 7 "EPB_TELLTALE_SNA" 4 "EPB_TELLTALE_LAMP_RED_FLASH" 3 "EPB_TELLTALE_LAMP_AMBER_ON" 2 "EPB_TELLTALE_LAMP_RED_ON" 1 "EPB_TELLTALE_LAMP_RED_PARKED" 0 "EPB_TELLTALE_LAMP_OFF" ;
VAL_ 680 EPBL_cdpRequest 1 "EPB_CDP_REQUESTED" 0 "EPB_CDP_NOT_REQUESTED" ;
VAL_ 680 EPBL_uiParkAvailable 2 "EPB_AVAIL_REAPPLIED" 1 "EPB_AVAIL_AVAILABLE" 0 "EPB_AVAIL_NOT_AVAILABLE" ;
VAL_ 680 EPBL_brakeDiscWipeRequest 3 "EPB_BRAKEDISCWIPE_REQUEST_SNA" 2 "EPB_BRAKEDISCWIPE_REQUEST_STRONG" 1 "EPB_BRAKEDISCWIPE_REQUEST_LIGHT" 0 "EPB_BRAKEDISCWIPE_REQUEST_NONE" ;
VAL_ 680 EPBL_uiWinchModeLvStatus 3 "EPB_LV_OK" 2 "EPB_LV_BLOCKED_TIMER_RUNNING" 1 "EPB_LV_BLOCKED_INPUT_VOLTAGE_LOW" 0 "EPB_LV_BLOCKED_BATTERY" ;
VAL_ 680 EPBL_autonomyBehavior 2 "DRIVERLESS_NO_TAKEOVER" 1 "DRIVERLESS_TAKEOVER" 0 "DRIVER" ;
